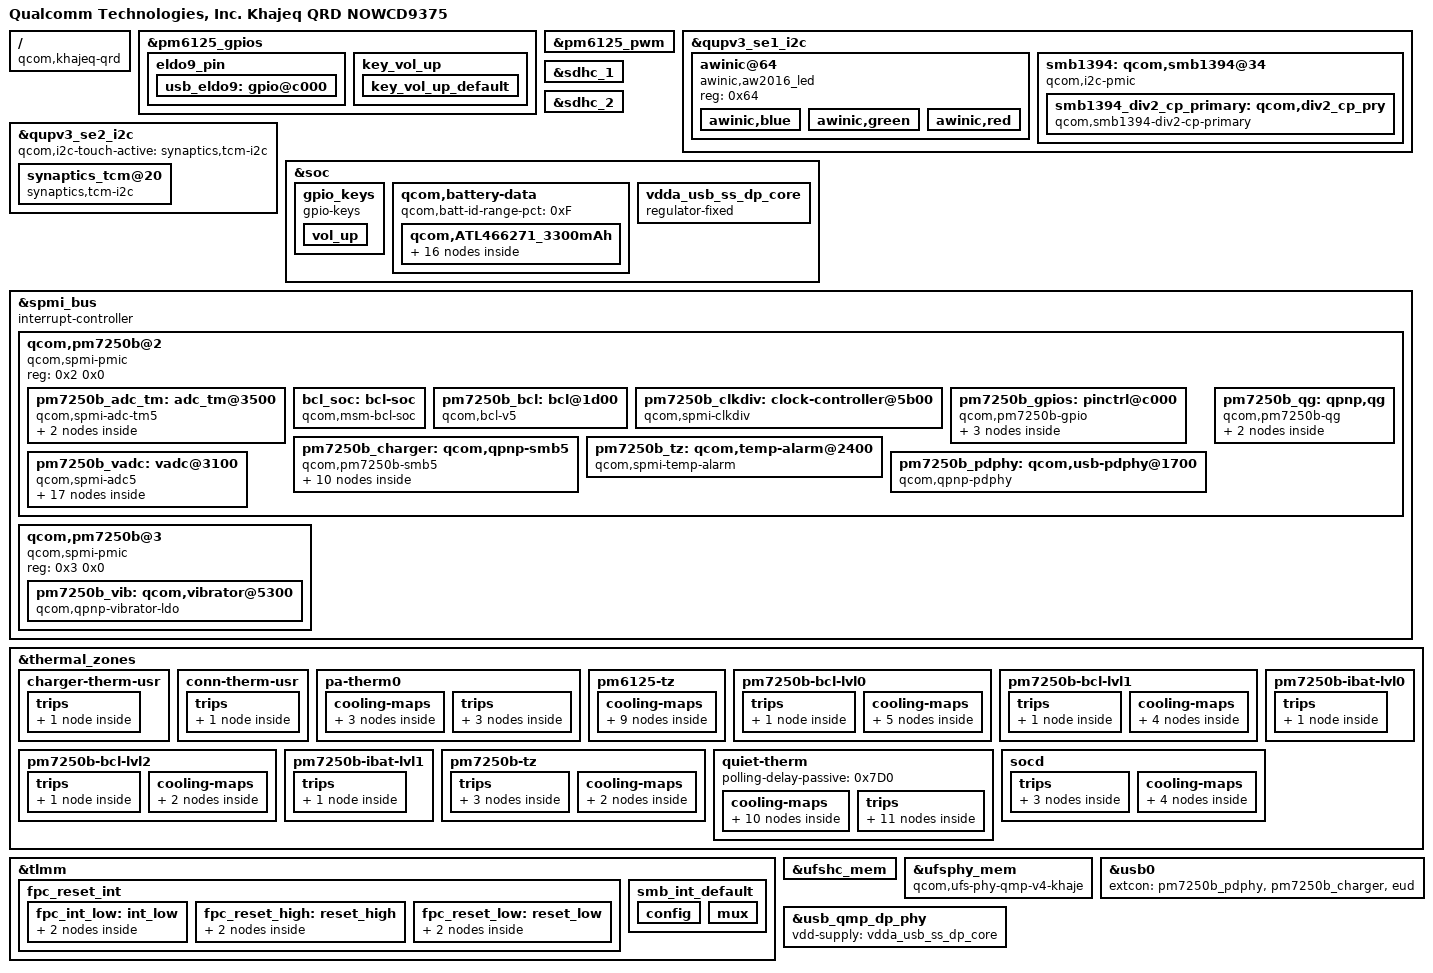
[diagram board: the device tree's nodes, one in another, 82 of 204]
/dts-v1/;

/ {
    compatible = "qcom,khajeq-qrd", "qcom,khajeq", "qcom,qrd";
    model = "Qualcomm Technologies, Inc. Khajeq QRD NOWCD9375";
    qcom,board-id = <0x2010B 0x0>;
    qcom,msm-id = <0x232 0x10000>;
    qcom,pmic-id = <0x2D 0x2E 0x0 0x0>;
};

&pm6125_gpios {
    eldo9_pin {
        usb_eldo9: gpio@c000 {
            bias-disable;
            function = "normal";
            output-high;
            pins = "gpio1";
            power-source = <0x0>;
            qcom,drive-strength = <0x2>;
        };
    };
    key_vol_up {
        key_vol_up_default: key_vol_up_default {
            bias-pull-up;
            function = "normal";
            input-enable;
            pins = "gpio5";
            power-source = <0x0>;
        };
    };
};

&pm6125_pwm {
    status = "ok";
};

&qupv3_se1_i2c {
    status = "ok";
    awinic@64 {
        compatible = "awinic,aw2016_led";
        reg = <0x64>;
        awinic,blue {
            awinic,fall-time-ms = <0x6>;
            awinic,hold-time-ms = <0x0>;
            awinic,id = <0x2>;
            awinic,imax = <0x2>;
            awinic,led-current = <0x3>;
            awinic,max-brightness = <0xFF>;
            awinic,name = "blue";
            awinic,off-time-ms = <0x4>;
            awinic,rise-time-ms = <0x6>;
        };
        awinic,green {
            awinic,fall-time-ms = <0x6>;
            awinic,hold-time-ms = <0x0>;
            awinic,id = <0x1>;
            awinic,imax = <0x2>;
            awinic,led-current = <0x3>;
            awinic,max-brightness = <0xFF>;
            awinic,name = "green";
            awinic,off-time-ms = <0x4>;
            awinic,rise-time-ms = <0x6>;
        };
        awinic,red {
            awinic,fall-time-ms = <0x6>;
            awinic,hold-time-ms = <0x0>;
            awinic,id = <0x0>;
            awinic,imax = <0x2>;
            awinic,led-current = <0x3>;
            awinic,max-brightness = <0xFF>;
            awinic,name = "red";
            awinic,off-time-ms = <0x4>;
            awinic,rise-time-ms = <0x6>;
        };
    };
    smb1394: qcom,smb1394@34 {
        #address-cells = <0x1>;
        #interrupt-cells = <0x3>;
        #size-cells = <0x0>;
        compatible = "qcom,i2c-pmic";
        interrupt-controller;
        interrupt-names = "smb1394";
        interrupt-parent = <&spmi_bus>;
        interrupts = <0x2 0xC5 0x0 0x8>;
        pinctrl-0 = <&pm7250b_smb_int_default>;
        pinctrl-names = "default";
        qcom,enable-toggle-stat;
        qcom,periph-map = <0x6 0x26 0x27>;
        reg = <0x34>;
        status = "ok";
        smb1394_div2_cp_primary: qcom,div2_cp_pry {
            #io-channel-cells = <0x1>;
            compatible = "qcom,smb1394-div2-cp-primary";
            interrupt-names = "temp-shdwn", "div2-irev", "usbin-uv", "usbin-ov", "div2-ilim", "div2-win-uv", "div2-win-ov";
            interrupts = <0x26 0x1 0x1 0x26 0x3 0x1 0x26 0x5 0x1 0x26 0x7 0x1 0x27 0x5 0x1 0x27 0x6 0x1 0x27 0x7 0x1>;
            io-channel-names = "die_temp";
            io-channels = <&pm7250b_vadc 0xE>;
            qcom,div2-cp-min-ilim-ua = <0xF4240>;
            qcom,parallel-input-mode = <0x1>;
            qcom,parallel-output-mode = <0x2>;
            status = "ok";
        };
    };
};

&qupv3_se2_i2c {
    qcom,i2c-touch-active = "synaptics,tcm-i2c";
    status = "okay";
    synaptics_tcm@20 {
        compatible = "synaptics,tcm-i2c";
        interrupt-parent = <&tlmm>;
        interrupts = <0x50 0x2008>;
        pinctrl-0 = <&ts_int_active &ts_reset_active>;
        pinctrl-1 = <&ts_int_suspend &ts_reset_suspend>;
        pinctrl-2 = <&ts_release>;
        pinctrl-names = "pmx_ts_active", "pmx_ts_suspend", "pmx_ts_release";
        reg = <0x20>;
        synaptics,extend_report;
        synaptics,firmware-name = "synaptics_firmware_k.img";
        synaptics,irq-gpio = <&tlmm 0x50 0x2008>;
        synaptics,irq-on-state = <0x0>;
        synaptics,power-delay-ms = <0xC8>;
        synaptics,reset-active-ms = <0x14>;
        synaptics,reset-delay-ms = <0xC8>;
        synaptics,reset-gpio = <&tlmm 0x56 0x0>;
        synaptics,reset-on-state = <0x0>;
        synaptics,ubl-i2c-addr = <0x20>;
    };
};

&sdhc_1 {
    pinctrl-0 = <&sdc1_on>;
    pinctrl-1 = <&sdc1_off>;
    pinctrl-names = "default", "sleep";
    qcom,vdd-current-level = <0x0 0x8B290>;
    qcom,vdd-io-always-on;
    qcom,vdd-io-current-level = <0x0 0x4F588>;
    qcom,vdd-io-lpm-sup;
    qcom,vdd-io-voltage-level = <0x1B7740 0x1B7740>;
    qcom,vdd-voltage-level = <0x2D2A80 0x2D2A80>;
    status = "ok";
    vdd-io-supply = <&L11A>;
    vdd-supply = <&L24A>;
};

&sdhc_2 {
    cd-gpios = <&tlmm 0x58 0x1>;
    pinctrl-0 = <&sdc2_on>;
    pinctrl-1 = <&sdc2_off>;
    pinctrl-names = "default", "sleep";
    qcom,vdd-current-level = <0x0 0xC3500>;
    qcom,vdd-io-bias-current-level = <0x0 0x1770>;
    qcom,vdd-io-bias-voltage-level = <0x132A40 0x132A40>;
    qcom,vdd-io-current-level = <0x0 0x55F0>;
    qcom,vdd-io-voltage-level = <0x1B7740 0x2D2A80>;
    qcom,vdd-voltage-level = <0x2D2A80 0x2D2A80>;
    status = "ok";
    vdd-io-bias-supply = <&L7A>;
    vdd-io-supply = <&L5A>;
    vdd-supply = <&L22A>;
};

&soc {
    gpio_keys {
        compatible = "gpio-keys";
        label = "gpio-keys";
        pinctrl-0 = <&key_vol_up_default>;
        pinctrl-names = "default";
        vol_up {
            debounce-interval = <0xF>;
            gpio-key,wakeup;
            gpios = <&pm6125_gpios 0x5 0x1>;
            label = "volume_up";
            linux,can-disable;
            linux,code = <0x73>;
            linux,input-type = <0x1>;
        };
    };
    qcom,battery-data {
        qcom,batt-id-range-pct = <0xF>;
        qcom,ATL466271_3300mAh {
            qcom,batt-id-kohm = <0x18>;
            qcom,battery-beta = <0x109A>;
            qcom,battery-therm-kohm = <0x64>;
            qcom,battery-type = "ATL466271_3300mAh_averaged_MasterSlave_Jun12th2019";
            qcom,fastchg-current-ma = <0x1F40>;
            qcom,fg-cc-cv-threshold-uv = <0x42FC70>;
            qcom,jeita-fcc-ranges = <0x0 0x64 0x186A00 0x65 0xC8 0x30D400 0xC9 0x1C2 0x7A1200 0x1C3 0x226 0x186A00>;
            qcom,jeita-fv-ranges = <0x0 0x64 0x432380 0x65 0xC8 0x432380 0xC9 0x1C2 0x432380 0x1C3 0x226 0x3DCC50>;
            qcom,jeita-hard-thresholds = <0x58CD 0x181D>;
            qcom,jeita-soft-fcc-ua = <0x186A00 0x186A00>;
            qcom,jeita-soft-fv-uv = <0x432380 0x3DCC50>;
            qcom,jeita-soft-hys-thresholds = <0x48D4 0x23C0>;
            qcom,jeita-soft-thresholds = <0x4CCC 0x20B8>;
            qcom,max-voltage-uv = <0x432380>;
            qcom,ocv-based-step-chg;
            qcom,qg-batt-profile-ver = <0x64>;
            qcom,step-chg-ranges = <0x3567E0 0x3D0900 0x7A1200 0x3D0901 0x401640 0x5B8D80 0x401641 0x432380 0x3D0900>;
            qcom,fcc1-temp-lut {
                qcom,lut-col-legend = <0x0 0xA 0x19 0x28 0x32>;
                qcom,lut-data = <0xC77 0xCBC 0xCF8 0xD1A 0xD26>;
            };
            qcom,fcc2-temp-lut {
                qcom,lut-col-legend = <0xFFFFFFF6 0x0 0xA 0x19 0x28 0x32>;
                qcom,lut-data = <0xCEB 0xCED 0xCFC 0xD04 0xD02 0xCFE>;
            };
            qcom,pc-temp-v1-lut {
                qcom,lut-col-legend = <0x0 0xA 0x19 0x28 0x32>;
                qcom,lut-data = <0xAABE 0xAB31 0xAB85 0xABA1 0xABA6 0xA9D1 0xAA55 0xAABA 0xAAC9 0xAACB 0xA8E5 0xA974 0xA9E1 0xA9F5 0xA9F6 0xA7FB 0xA88E 0xA903 0xA91E 0xA923 0xA717 0xA7A6 0xA81E 0xA83E 0xA847 0xA636 0xA6BF 0xA734 0xA755 0xA762 0xA558 0xA5D9 0xA64D 0xA66E 0xA67C 0xA47D 0xA4F6 0xA565 0xA587 0xA596 0xA3A6 0xA418 0xA481 0xA4A1 0xA4B1 0xA2D4 0xA33D 0xA39E 0xA3BD 0xA3CD 0xA204 0xA266 0xA2BF 0xA2DA 0xA2E9 0xA13E 0xA190 0xA1E6 0xA1FB 0xA209 0xA08F 0xA0C7 0xA110 0xA11F 0xA12D 0x9FEF 0xA01B 0xA043 0xA04B 0xA057 0x9F34 0x9F77 0x9F7F 0x9F81 0x9F88 0x9E33 0x9EB1 0x9EBE 0x9EBF 0x9EC2 0x9D2B 0x9DB3 0x9DF2 0x9DFA 0x9E00 0x9C6F 0x9CC8 0x9D20 0x9D31 0x9D43 0x9BE1 0x9C2A 0x9C67 0x9C75 0x9C8C 0x9B5A 0x9BA5 0x9BD5 0x9BD6 0x9BE5 0x9AD5 0x9AF4 0x9B3E 0x9B3E 0x9B44 0x9A4A 0x99EA 0x9A67 0x9A7A 0x9A82 0x9997 0x98F7 0x995C 0x9976 0x9983 0x9891 0x986A 0x9890 0x9896 0x989E 0x97B9 0x9802 0x9804 0x97FD 0x9801 0x975C 0x979E 0x978E 0x977F 0x9782 0x9720 0x973A 0x971E 0x970C 0x970B 0x96E4 0x96DD 0x96B8 0x96A6 0x969F 0x96A6 0x9688 0x965B 0x9647 0x963C 0x9668 0x963B 0x9606 0x95EC 0x95DF 0x962D 0x95F7 0x95BA 0x9599 0x958A 0x95F4 0x95BA 0x9575 0x954F 0x953D 0x95C1 0x9584 0x9537 0x950C 0x94F6 0x9594 0x9554 0x94FF 0x94CF 0x94B4 0x956B 0x952B 0x94CF 0x949B 0x9479 0x9546 0x9502 0x94A1 0x9468 0x943F 0x9526 0x94DF 0x9474 0x942D 0x93F9 0x94FF 0x94B7 0x9446 0x93ED 0x93A8 0x94BA 0x9476 0x9407 0x93A1 0x934F 0x9456 0x940F 0x93AA 0x9341 0x92EE 0x93E8 0x939C 0x933C 0x92D3 0x9282 0x9368 0x931F 0x92C3 0x9251 0x9200 0x92D8 0x9292 0x9239 0x91BE 0x916C 0x9233 0x91E7 0x9196 0x9120 0x90CF 0x91AD 0x9162 0x910F 0x90AD 0x9064 0x9162 0x911C 0x90C5 0x9070 0x9036 0x914D 0x9107 0x90B3 0x905E 0x9023 0x9138 0x90FA 0x90A3 0x9051 0x9014 0x9120 0x90DE 0x908D 0x9033 0x8FED 0x90BD 0x905A 0x900F 0x8F73 0x8F0F 0x8F42 0x8EE2 0x8EAE 0x8DFB 0x8D92 0x8D63 0x8CF6 0x8CC9 0x8C13 0x8BA7 0x8AF6 0x8A79 0x8A63 0x899D 0x892C 0x87A9 0x870E 0x870E 0x863A 0x85C2 0x8279 0x8194 0x81C9 0x80DD 0x8053 0x7530 0x7530 0x7530 0x7530 0x7530>;
                qcom,lut-row-legend = <0x2710 0x2648 0x2580 0x24B8 0x23F0 0x2328 0x2260 0x2198 0x20D0 0x2008 0x1F40 0x1E78 0x1DB0 0x1CE8 0x1C20 0x1B58 0x1A90 0x19C8 0x1900 0x1838 0x1770 0x16A8 0x15E0 0x1518 0x1450 0x1388 0x12C0 0x11F8 0x1130 0x1068 0xFA0 0xED8 0xE10 0xD48 0xC80 0xBB8 0xAF0 0xA28 0x960 0x898 0x7D0 0x708 0x640 0x578 0x4B0 0x3E8 0x384 0x320 0x2BC 0x258 0x1F4 0x190 0x12C 0xC8 0x64 0x0>;
            };
            qcom,pc-temp-v2-lut {
                qcom,lut-col-legend = <0xFFFFFFF6 0x0 0xA 0x19 0x28 0x32>;
                qcom,lut-data = <0xABC7 0xABAE 0xAB9A 0xAB81 0xAB4F 0xAB3B 0xAA5E 0xAA7F 0xAA93 0xAA8F 0xAA61 0xAA4C 0xA90F 0xA961 0xA992 0xA9A0 0xA977 0xA962 0xA7DC 0xA854 0xA89A 0xA8B4 0xA88E 0xA87A 0xA6C0 0xA759 0xA7A9 0xA7CC 0xA7A9 0xA797 0xA5C0 0xA664 0xA6BA 0xA6E4 0xA6C3 0xA6B3 0xA4EC 0xA56E 0xA5CE 0xA5FA 0xA5DA 0xA5CB 0xA424 0xA47E 0xA4E4 0xA511 0xA4F1 0xA4E2 0xA32C 0xA399 0xA3FE 0xA42B 0xA40B 0xA3FC 0xA1F2 0xA2BE 0xA31B 0xA347 0xA326 0xA317 0xA113 0xA1E8 0xA23B 0xA266 0xA245 0xA236 0xA0C1 0xA113 0xA15E 0xA188 0xA166 0xA159 0xA080 0xA042 0xA086 0xA0AE 0xA08C 0xA07F 0x9FC8 0x9F80 0x9FC3 0x9FE2 0x9FBD 0x9FAD 0x9DFF 0x9ECD 0x9F10 0x9F20 0x9EF6 0x9EE0 0x9C62 0x9E0A 0x9E4D 0x9E59 0x9E2F 0x9E18 0x9B6C 0x9D1D 0x9D64 0x9D7F 0x9D60 0x9D55 0x9AA1 0x9C1F 0x9C72 0x9CAA 0x9C97 0x9C98 0x99EE 0x9B36 0x9BA1 0x9BF6 0x9BE8 0x9BE9 0x9950 0x9A5B 0x9AE4 0x9B57 0x9B4A 0x9B46 0x98A2 0x9989 0x9A20 0x9A9F 0x9A94 0x9A8E 0x97B0 0x98BC 0x9940 0x99A8 0x99A0 0x999B 0x96B8 0x97FC 0x9869 0x98B1 0x98AA 0x98A8 0x961A 0x975B 0x97BD 0x97FA 0x97F7 0x97F5 0x95A6 0x96D1 0x972B 0x9760 0x9763 0x9762 0x9552 0x964D 0x96AA 0x96DD 0x96E3 0x96E1 0x9514 0x95BF 0x9635 0x966A 0x9671 0x966F 0x94E1 0x953C 0x95CC 0x9603 0x960A 0x9607 0x94AE 0x94E0 0x956D 0x95A4 0x95AA 0x95A7 0x947E 0x949B 0x9516 0x954D 0x9550 0x954C 0x9450 0x9464 0x94C2 0x94FC 0x94FE 0x94F9 0x9425 0x9436 0x946C 0x94B0 0x94B3 0x94AE 0x93FA 0x940D 0x9421 0x9469 0x946B 0x9465 0x93CC 0x93E5 0x93EE 0x9425 0x9426 0x941A 0x939D 0x93BF 0x93C7 0x93E3 0x93E2 0x93CD 0x936B 0x9395 0x939E 0x939D 0x938F 0x9371 0x9338 0x9367 0x9373 0x9353 0x9324 0x92F9 0x92FF 0x9332 0x9342 0x9305 0x92B7 0x9281 0x92BA 0x92F3 0x9300 0x92B7 0x925D 0x9222 0x9268 0x92A6 0x92AB 0x9265 0x920A 0x91CD 0x9209 0x9249 0x9247 0x9206 0x91AA 0x916C 0x9194 0x91C9 0x91CA 0x9195 0x913A 0x90F9 0x9118 0x9139 0x913D 0x910F 0x90B5 0x9073 0x90A3 0x90A2 0x90A1 0x907B 0x901F 0x8FDE 0x9044 0x9036 0x904B 0x902C 0x8FE9 0x8FB0 0x8FF7 0x8FF9 0x9023 0x9015 0x8FD2 0x8F9A 0x8FCC 0x8FDB 0x900B 0x9003 0x8FC1 0x8F8D 0x8F99 0x8FB2 0x8FEE 0x8FEB 0x8FAB 0x8F72 0x8F47 0x8F71 0x8FA7 0x8FAB 0x8F54 0x8EF5 0x8E7B 0x8EC7 0x8EC2 0x8EC8 0x8E26 0x8DA8 0x8CE2 0x8D4D 0x8D1F 0x8D25 0x8C61 0x8BD5 0x8AAB 0x8B3F 0x8AFB 0x8B0C 0x8A2A 0x898B 0x87CE 0x8898 0x882F 0x885D 0x8749 0x8695 0x83F8 0x84E8 0x848F 0x84CC 0x837A 0x8280 0x7E9C 0x7FC7 0x7F37 0x7F8A 0x7C60 0x7A4F 0x6E37 0x709F 0x6B82 0x6FA3 0x6CA6 0x6B7E>;
                qcom,lut-row-legend = <0x2710 0x2648 0x2580 0x24B8 0x23F0 0x2328 0x2260 0x2198 0x20D0 0x2008 0x1F40 0x1E78 0x1DB0 0x1CE8 0x1C20 0x1B58 0x1A90 0x19C8 0x1900 0x1838 0x1770 0x16A8 0x15E0 0x1518 0x1450 0x1388 0x12C0 0x11F8 0x1130 0x1068 0xFA0 0xED8 0xE10 0xD48 0xC80 0xBB8 0xAF0 0xA28 0x960 0x898 0x7D0 0x708 0x640 0x578 0x4B0 0x3E8 0x384 0x320 0x2BC 0x258 0x1F4 0x190 0x12C 0xC8 0x64 0x0>;
            };
            qcom,pc-temp-y1-lut {
                qcom,lut-col-legend = <0xFFFFFFF6 0x0 0xA 0x19 0x28 0x32>;
                qcom,lut-data = <0x16BD 0x14E3 0x13AD 0x1242 0x1181 0x114B 0x16D3 0x14E7 0x13AC 0x1240 0x1184 0x114D 0x16E9 0x14EB 0x13AB 0x123E 0x1185 0x114E 0x16FB 0x14F1 0x13A9 0x123B 0x1185 0x114E 0x1709 0x14F5 0x13A7 0x1238 0x1184 0x114F 0x170F 0x14F7 0x13A6 0x1234 0x1182 0x114F 0x170C 0x14F7 0x13A1 0x1230 0x117D 0x114E 0x1707 0x14F5 0x139B 0x122A 0x1179 0x114D 0x1708 0x14F4 0x1396 0x1226 0x1178 0x114B 0x170D 0x14EF 0x1392 0x1223 0x1178 0x1149 0x170F 0x14EC 0x1390 0x1220 0x1178 0x1147 0x1710 0x14EE 0x1393 0x121D 0x1176 0x1146 0x1714 0x14F1 0x1397 0x121A 0x1174 0x1146 0x1717 0x14F1 0x1395 0x1218 0x1173 0x1145 0x1720 0x14EF 0x138C 0x1216 0x1171 0x1143 0x1725 0x14EE 0x1388 0x1215 0x1170 0x1143 0x1722 0x14F5 0x138B 0x1215 0x1170 0x1143 0x171D 0x14FE 0x138F 0x1215 0x1170 0x1143 0x171D 0x1500 0x1390 0x1215 0x1170 0x1143 0x171C 0x14FD 0x138D 0x1216 0x1171 0x1143 0x171A 0x14FC 0x138B 0x1217 0x1171 0x1143 0x171A 0x1501 0x138C 0x1219 0x1173 0x1144 0x171C 0x1506 0x138D 0x121B 0x1175 0x1146 0x171D 0x1507 0x138D 0x121E 0x1175 0x1146 0x171D 0x1506 0x138E 0x1220 0x1175 0x1146 0x171D 0x1506 0x1390 0x1223 0x1176 0x1147 0x171B 0x150E 0x1395 0x1226 0x1178 0x1147 0x1717 0x1518 0x139B 0x122A 0x117A 0x1148 0x1713 0x1519 0x13A0 0x122E 0x117C 0x114A 0x170C 0x1516 0x13A5 0x1233 0x117F 0x114C 0x1708 0x1513 0x13A8 0x1238 0x1181 0x114E 0x1712 0x1513 0x13A8 0x123D 0x1184 0x114F 0x1722 0x1516 0x13A8 0x1243 0x1187 0x1150 0x172C 0x1519 0x13AB 0x1247 0x118A 0x1152 0x1737 0x151B 0x13B3 0x124A 0x118D 0x1155 0x173A 0x151D 0x13B7 0x124E 0x1190 0x1158 0x172D 0x1519 0x13B7 0x1253 0x1193 0x115A 0x1718 0x1513 0x13B8 0x1257 0x1195 0x115C 0x170D 0x1511 0x13BD 0x125D 0x1198 0x115D 0x1704 0x1511 0x13C5 0x1263 0x119A 0x115E 0x16FF 0x1511 0x13C9 0x1266 0x119D 0x1160 0x1708 0x1512 0x13C8 0x1269 0x119F 0x1163 0x170C 0x1516 0x13CA 0x126B 0x11A1 0x1163 0x16FB 0x152A 0x13D7 0x126D 0x11A3 0x1163 0x171B 0x1522 0x13D3 0x1275 0x11A6 0x1166 0x1712 0x1517 0x13E1 0x1276 0x11A9 0x1168 0x170B 0x151A 0x13E0 0x1277 0x11A7 0x1169 0x1705 0x1518 0x13D9 0x127E 0x11AA 0x1169 0x1706 0x1528 0x13DA 0x1281 0x11A9 0x1169 0x1705 0x152E 0x13E1 0x127F 0x11AB 0x116A 0x173F 0x151B 0x13EB 0x1282 0x11AD 0x116C 0x175A 0x1523 0x13EC 0x1290 0x11B1 0x116E 0x1737 0x151E 0x13F3 0x128C 0x11B6 0x1170 0x1743 0x152C 0x13F4 0x1295 0x11B8 0x1175 0x1743 0x152C 0x13F4 0x1295 0x11B8 0x1175 0x1743 0x152C 0x13F4 0x1295 0x11B8 0x1175>;
                qcom,lut-row-legend = <0x2710 0x2648 0x2580 0x24B8 0x23F0 0x2328 0x2260 0x2198 0x20D0 0x2008 0x1F40 0x1E78 0x1DB0 0x1CE8 0x1C20 0x1B58 0x1A90 0x19C8 0x1900 0x1838 0x1770 0x16A8 0x15E0 0x1518 0x1450 0x1388 0x12C0 0x11F8 0x1130 0x1068 0xFA0 0xED8 0xE10 0xD48 0xC80 0xBB8 0xAF0 0xA28 0x960 0x898 0x7D0 0x708 0x640 0x578 0x4B0 0x3E8 0x384 0x320 0x2BC 0x258 0x1F4 0x190 0x12C 0xC8 0x64 0x0>;
            };
            qcom,pc-temp-y2-lut {
                qcom,lut-col-legend = <0xFFFFFFF6 0x0 0xA 0x19 0x28 0x32>;
                qcom,lut-data = <0x276B 0x2807 0x290D 0x2A0F 0x2A21 0x2AAF 0x2765 0x2813 0x2904 0x29F4 0x2A37 0x2ACE 0x2762 0x2822 0x28F9 0x29D7 0x2A42 0x2ADE 0x2762 0x2830 0x28EF 0x29BC 0x2A45 0x2AE2 0x2764 0x283D 0x28E6 0x29A5 0x2A42 0x2ADE 0x2768 0x2845 0x28DF 0x2993 0x2A3D 0x2AD7 0x2791 0x284A 0x28DA 0x2986 0x2A23 0x2AC4 0x27D4 0x284E 0x28D6 0x297B 0x2A02 0x2AA8 0x2802 0x284D 0x28D4 0x296E 0x29FC 0x2A8B 0x2845 0x2846 0x28D0 0x295D 0x29FD 0x2A66 0x2867 0x2842 0x28CE 0x2952 0x29FE 0x2A51 0x286C 0x286D 0x28D3 0x2955 0x29F8 0x2A52 0x2879 0x28C1 0x28DE 0x295C 0x29EF 0x2A55 0x2872 0x2914 0x28F2 0x295C 0x29EE 0x2A51 0x281B 0x2979 0x291D 0x2959 0x29ED 0x2A46 0x27D4 0x29AF 0x2951 0x295F 0x29ED 0x2A40 0x2709 0x29B5 0x2996 0x297E 0x29ED 0x2A48 0x25FC 0x29B7 0x29D5 0x29AE 0x29EE 0x2A55 0x25CD 0x29BA 0x29EC 0x29F5 0x29EC 0x2A5F 0x25C7 0x29C1 0x29F9 0x2A59 0x29E9 0x2A69 0x25C4 0x29C4 0x29FE 0x2A7D 0x29F0 0x2A79 0x25C2 0x29C7 0x29FB 0x2A4C 0x2A51 0x2AA2 0x25C0 0x29CD 0x29F7 0x2A17 0x2ABC 0x2AD5 0x25BF 0x29CA 0x2A02 0x2A20 0x2ACC 0x2AF7 0x25BD 0x29B4 0x2A19 0x2A48 0x2AD0 0x2B16 0x25BC 0x2990 0x2A28 0x2A69 0x2AD5 0x2B2E 0x25BB 0x2937 0x2A2E 0x2A80 0x2ADC 0x2B46 0x25BA 0x28B0 0x2A35 0x2A94 0x2AE4 0x2B5E 0x25B9 0x282F 0x2A44 0x2AA4 0x2AF2 0x2B71 0x25B8 0x2796 0x2A5F 0x2AB2 0x2B0D 0x2B81 0x25B8 0x271A 0x2A6A 0x2AC4 0x2B28 0x2B94 0x25B7 0x26B9 0x2A5C 0x2AED 0x2B45 0x2BB1 0x25B7 0x2669 0x2A48 0x2B0E 0x2B61 0x2BCA 0x25B6 0x263F 0x2A37 0x2B0D 0x2B81 0x2BD4 0x25B6 0x2621 0x2A22 0x2B03 0x2BA2 0x2BDA 0x25B6 0x2609 0x2A10 0x2AFD 0x2BA9 0x2BDC 0x25B6 0x25F4 0x2A01 0x2B03 0x2B83 0x2BC0 0x25B6 0x25E3 0x29F1 0x2B09 0x2B5E 0x2BA2 0x25B5 0x25D9 0x29D8 0x2B04 0x2B58 0x2B99 0x25B5 0x25D1 0x29B3 0x2AF4 0x2B55 0x2B88 0x25B5 0x25CB 0x2978 0x2AE4 0x2B49 0x2B6E 0x25B5 0x25C7 0x28FB 0x2AD1 0x2B18 0x2B3A 0x25B5 0x25C3 0x2889 0x2AB8 0x2B01 0x2B30 0x25B5 0x25C0 0x282C 0x2A96 0x2AFA 0x2B58 0x25B5 0x25BD 0x27DD 0x2A73 0x2AF8 0x2AF5 0x25B4 0x25BB 0x27CD 0x2A44 0x2AB7 0x2ABD 0x25B4 0x25BB 0x27BA 0x2A5A 0x2A80 0x2A9B 0x25B4 0x25BA 0x281A 0x2A22 0x2A9B 0x2A92 0x25B4 0x25B9 0x2866 0x2A43 0x2AAE 0x2A9C 0x25B4 0x25B8 0x280A 0x2A47 0x2A7B 0x2A63 0x25B4 0x25B7 0x2735 0x29FE 0x2A4D 0x2A32 0x25B4 0x25B6 0x26F4 0x299B 0x29FE 0x2A0E 0x25B3 0x25B5 0x26A3 0x29EF 0x29C2 0x29B3 0x25B2 0x25B5 0x27BB 0x29B7 0x2949 0x2930 0x25B2 0x25B5 0x27BB 0x29B7 0x2949 0x2930 0x25B2 0x25B5 0x27BB 0x29B7 0x2949 0x2930>;
                qcom,lut-row-legend = <0x2710 0x2648 0x2580 0x24B8 0x23F0 0x2328 0x2260 0x2198 0x20D0 0x2008 0x1F40 0x1E78 0x1DB0 0x1CE8 0x1C20 0x1B58 0x1A90 0x19C8 0x1900 0x1838 0x1770 0x16A8 0x15E0 0x1518 0x1450 0x1388 0x12C0 0x11F8 0x1130 0x1068 0xFA0 0xED8 0xE10 0xD48 0xC80 0xBB8 0xAF0 0xA28 0x960 0x898 0x7D0 0x708 0x640 0x578 0x4B0 0x3E8 0x384 0x320 0x2BC 0x258 0x1F4 0x190 0x12C 0xC8 0x64 0x0>;
            };
            qcom,pc-temp-y3-lut {
                qcom,lut-col-legend = <0xFFFFFFF6 0x0 0xA 0x19 0x28 0x32>;
                qcom,lut-data = <0x36C4 0x34AD 0x3424 0x33EA 0x33DC 0x33D5 0x3658 0x34AC 0x3426 0x33EA 0x33DC 0x33D6 0x3617 0x34AA 0x3427 0x33EA 0x33DD 0x33D7 0x35F6 0x34A9 0x3428 0x33EA 0x33DD 0x33D8 0x35EA 0x34A7 0x3429 0x33EA 0x33DE 0x33DA 0x35E8 0x34A5 0x3429 0x33EA 0x33DE 0x33DA 0x3616 0x34A2 0x3429 0x33EA 0x33DE 0x33DB 0x365B 0x349F 0x3429 0x33E9 0x33DF 0x33DB 0x3639 0x34A0 0x3429 0x33EA 0x33DF 0x33DB 0x354E 0x34A5 0x3428 0x33EB 0x33DF 0x33DB 0x34BB 0x34A8 0x3427 0x33EC 0x33E0 0x33DB 0x34DF 0x349E 0x3427 0x33EE 0x33E0 0x33DC 0x3518 0x348E 0x3427 0x33F0 0x33E0 0x33DD 0x3525 0x3489 0x3428 0x33F1 0x33E1 0x33DD 0x3515 0x3482 0x342C 0x33F1 0x33E2 0x33DD 0x3506 0x347C 0x342E 0x33F2 0x33E2 0x33DD 0x34E8 0x347A 0x3428 0x33F2 0x33E2 0x33DD 0x34C3 0x3475 0x341F 0x33F4 0x33E3 0x33DD 0x34BF 0x346D 0x341D 0x33F5 0x33E4 0x33DE 0x34C6 0x345B 0x341C 0x33F6 0x33E5 0x33E0 0x34CD 0x3449 0x341A 0x33F7 0x33E6 0x33E1 0x34D1 0x343C 0x3413 0x33F2 0x33E2 0x33DE 0x34D3 0x3431 0x340B 0x33EB 0x33DE 0x33DB 0x34D3 0x3428 0x3407 0x33E8 0x33DD 0x33DA 0x34DD 0x3421 0x3404 0x33E6 0x33DD 0x33D9 0x34F1 0x341A 0x3402 0x33E5 0x33DC 0x33D8 0x3519 0x3408 0x33FF 0x33E5 0x33DD 0x33D9 0x354E 0x33F3 0x33FD 0x33E5 0x33DD 0x33D9 0x3580 0x33E8 0x33FC 0x33E5 0x33DC 0x33D9 0x35B6 0x33D7 0x33FB 0x33E6 0x33DC 0x33D9 0x35EE 0x33D2 0x33F9 0x33E6 0x33DB 0x33D9 0x362A 0x33D4 0x33F7 0x33E5 0x33DB 0x33D9 0x3669 0x33D7 0x33F5 0x33E5 0x33DB 0x33D8 0x36AA 0x33DA 0x33F5 0x33E5 0x33DB 0x33D8 0x36EC 0x33DE 0x33F7 0x33E4 0x33DC 0x33D8 0x3736 0x33E4 0x33F9 0x33E4 0x33DD 0x33D8 0x378C 0x33EF 0x33FB 0x33E3 0x33DC 0x33D9 0x37E8 0x33FF 0x33FD 0x33E2 0x33DB 0x33D9 0x3845 0x3414 0x33FF 0x33E2 0x33DB 0x33D9 0x38A5 0x3432 0x3400 0x33E2 0x33DC 0x33DA 0x3904 0x3451 0x3401 0x33E2 0x33DC 0x33DA 0x395F 0x3468 0x3401 0x33E2 0x33DD 0x33DA 0x39BD 0x3483 0x3402 0x33E3 0x33DD 0x33DA 0x3A24 0x34B0 0x3405 0x33E4 0x33DC 0x33D9 0x3A96 0x34FD 0x340A 0x33E5 0x33DC 0x33DA 0x3A8C 0x351C 0x340E 0x33E8 0x33DE 0x33DC 0x3AD3 0x3551 0x3412 0x33E9 0x33DF 0x33DD 0x3B30 0x3590 0x341B 0x33EE 0x33E3 0x33DF 0x3B8F 0x35D8 0x3427 0x33F0 0x33E2 0x33DD 0x3BEC 0x3617 0x3428 0x33EF 0x33E0 0x33DC 0x3C53 0x3662 0x342B 0x33EF 0x33E1 0x33DD 0x3D0B 0x36EC 0x3437 0x33F2 0x33E4 0x33DF 0x3DF9 0x37B2 0x3448 0x33F8 0x33E6 0x33E3 0x4115 0x38C2 0x3473 0x3400 0x33EB 0x33E7 0x4115 0x38C2 0x3473 0x3400 0x33EB 0x33E7 0x4115 0x38C2 0x3473 0x3400 0x33EB 0x33E7>;
                qcom,lut-row-legend = <0x2710 0x2648 0x2580 0x24B8 0x23F0 0x2328 0x2260 0x2198 0x20D0 0x2008 0x1F40 0x1E78 0x1DB0 0x1CE8 0x1C20 0x1B58 0x1A90 0x19C8 0x1900 0x1838 0x1770 0x16A8 0x15E0 0x1518 0x1450 0x1388 0x12C0 0x11F8 0x1130 0x1068 0xFA0 0xED8 0xE10 0xD48 0xC80 0xBB8 0xAF0 0xA28 0x960 0x898 0x7D0 0x708 0x640 0x578 0x4B0 0x3E8 0x384 0x320 0x2BC 0x258 0x1F4 0x190 0x12C 0xC8 0x64 0x0>;
            };
            qcom,pc-temp-y4-lut {
                qcom,lut-col-legend = <0xFFFFFFF6 0x0 0xA 0x19 0x28 0x32>;
                qcom,lut-data = <0x4658 0x4267 0x414E 0x4074 0x404C 0x4048 0x4698 0x42A9 0x414F 0x4071 0x404B 0x4046 0x46BF 0x42D5 0x414D 0x406D 0x4049 0x4044 0x46D3 0x42EF 0x414A 0x4069 0x4047 0x4043 0x46DA 0x42FC 0x4145 0x4066 0x4045 0x4041 0x46DB 0x4300 0x413F 0x4065 0x4045 0x4040 0x466D 0x42F1 0x4135 0x4066 0x4044 0x4040 0x45C7 0x42D8 0x412B 0x4066 0x4044 0x403F 0x45E8 0x42C9 0x4129 0x4068 0x4044 0x4040 0x473B 0x42BB 0x4128 0x406A 0x4046 0x4041 0x484C 0x42B5 0x4128 0x406C 0x4047 0x4042 0x48BB 0x42D7 0x412B 0x4070 0x4049 0x4043 0x490C 0x431C 0x4131 0x4075 0x404D 0x4044 0x48AF 0x436C 0x4148 0x407D 0x4052 0x4045 0x46BB 0x43E8 0x4192 0x408A 0x4059 0x4049 0x4566 0x4426 0x41CE 0x409A 0x4061 0x404E 0x4536 0x43E3 0x41F3 0x40AA 0x4067 0x4054 0x4517 0x436B 0x420C 0x40BE 0x4070 0x405B 0x44DD 0x4316 0x4209 0x40E5 0x4084 0x406A 0x447E 0x42D4 0x41F0 0x4123 0x40AA 0x4084 0x43FF 0x4292 0x41C9 0x4139 0x40B8 0x408E 0x4307 0x4243 0x416A 0x40F4 0x4097 0x4079 0x41FB 0x41F9 0x4104 0x409E 0x406C 0x405C 0x41A6 0x41CD 0x40DF 0x407B 0x4059 0x404F 0x4182 0x41B2 0x40CB 0x4064 0x404D 0x4046 0x4173 0x4192 0x40C4 0x405E 0x4049 0x4044 0x4171 0x4157 0x40C2 0x405F 0x4049 0x4044 0x4171 0x4121 0x40C2 0x4060 0x4049 0x4044 0x4174 0x411D 0x40C3 0x4063 0x404B 0x4045 0x417B 0x412D 0x40C5 0x406A 0x404E 0x4047 0x4183 0x4139 0x40C5 0x4071 0x4053 0x404A 0x418F 0x4141 0x40AE 0x407A 0x4059 0x4050 0x419D 0x414D 0x4097 0x4080 0x4061 0x4056 0x41AD 0x415C 0x409A 0x4083 0x4068 0x405B 0x41BF 0x4171 0x40A8 0x4085 0x406F 0x405F 0x41CE 0x4181 0x40B8 0x4083 0x406F 0x405F 0x41DA 0x418D 0x40CB 0x406D 0x405A 0x4051 0x41E5 0x4197 0x40D9 0x4059 0x4046 0x4043 0x41ED 0x419A 0x40D8 0x4056 0x4042 0x4043 0x41F3 0x4198 0x40D7 0x4054 0x4041 0x4044 0x41F5 0x4194 0x40D7 0x4055 0x4040 0x4044 0x41EC 0x4182 0x40E0 0x405A 0x4041 0x4043 0x41E1 0x4175 0x40EA 0x405F 0x4040 0x4040 0x41DC 0x4175 0x40F4 0x4061 0x403A 0x4033 0x41EF 0x4179 0x4105 0x4064 0x403C 0x4033 0x41FB 0x4195 0x410C 0x4072 0x4047 0x4045 0x422F 0x41BB 0x412A 0x407F 0x405B 0x4071 0x4276 0x41F1 0x415D 0x4099 0x4098 0x40B2 0x42B9 0x4250 0x41A2 0x40CE 0x40AD 0x4092 0x42C1 0x427C 0x41A0 0x40B3 0x405E 0x4053 0x4297 0x425F 0x41A1 0x40AA 0x405D 0x4055 0x4292 0x426E 0x41C2 0x40C8 0x4074 0x4068 0x42D1 0x42BA 0x4207 0x4109 0x40A9 0x40A0 0x4493 0x4351 0x42CC 0x41BC 0x417F 0x414E 0x4493 0x4351 0x42CC 0x41BC 0x417F 0x414E 0x4493 0x4351 0x42CC 0x41BC 0x417F 0x414E>;
                qcom,lut-row-legend = <0x2710 0x2648 0x2580 0x24B8 0x23F0 0x2328 0x2260 0x2198 0x20D0 0x2008 0x1F40 0x1E78 0x1DB0 0x1CE8 0x1C20 0x1B58 0x1A90 0x19C8 0x1900 0x1838 0x1770 0x16A8 0x15E0 0x1518 0x1450 0x1388 0x12C0 0x11F8 0x1130 0x1068 0xFA0 0xED8 0xE10 0xD48 0xC80 0xBB8 0xAF0 0xA28 0x960 0x898 0x7D0 0x708 0x640 0x578 0x4B0 0x3E8 0x384 0x320 0x2BC 0x258 0x1F4 0x190 0x12C 0xC8 0x64 0x0>;
            };
            qcom,pc-temp-y5-lut {
                qcom,lut-col-legend = <0xFFFFFFF6 0x0 0xA 0x19 0x28 0x32>;
                qcom,lut-data = <0x2DCF 0x2EA6 0x34C2 0x3F88 0x444D 0x35AF 0x2BB3 0x2F95 0x360A 0x3FB0 0x4531 0x3C53 0x2AC4 0x3098 0x374A 0x3F1A 0x4617 0x4249 0x2AC2 0x3191 0x3867 0x3E11 0x46DE 0x473E 0x2B6F 0x3261 0x3945 0x3CDC 0x4765 0x4ADC 0x2C8B 0x32EB 0x39C8 0x3BC4 0x478B 0x4CCD 0x30B1 0x332C 0x3A07 0x3A3F 0x4749 0x4D1B 0x35FE 0x335E 0x3A10 0x38B6 0x46C1 0x4C61 0x3566 0x33F5 0x399A 0x383B 0x45CB 0x4AA2 0x2DAF 0x3592 0x3854 0x3805 0x43D1 0x4729 0x28DE 0x3686 0x3710 0x37F6 0x41D5 0x44E7 0x2CED 0x333A 0x3627 0x38AA 0x4016 0x44BC 0x33A3 0x2E59 0x3538 0x3982 0x3E49 0x44CB 0x363C 0x2E2F 0x33DE 0x38A2 0x3C4B 0x438F 0x3618 0x31E6 0x31FD 0x357D 0x39F2 0x4097 0x357B 0x35B4 0x312D 0x33FD 0x3886 0x3DE5 0x336F 0x38DA 0x31CF 0x3416 0x37BF 0x3B27 0x312A 0x3B5B 0x3333 0x344E 0x373E 0x38EE 0x32DC 0x3B9A 0x364C 0x34FC 0x3748 0x38A8 0x384D 0x3AB3 0x3CA3 0x36F4 0x37AE 0x3927 0x3CAF 0x3A21 0x3FD6 0x3983 0x386E 0x3A1C 0x3CD7 0x3A4B 0x403C 0x3E29 0x3B30 0x3DAB 0x3AD5 0x3AA6 0x405E 0x420F 0x3F25 0x4203 0x3803 0x3B5D 0x4032 0x4223 0x4331 0x4443 0x302E 0x3D0B 0x3FD7 0x416A 0x479B 0x45EE 0x2C32 0x3E6A 0x3F8C 0x411B 0x4967 0x46BD 0x2C87 0x3C91 0x3EE4 0x40C5 0x4958 0x4704 0x2CF8 0x38B8 0x3E3E 0x4095 0x48B7 0x46F9 0x2D05 0x35A9 0x3E9C 0x415A 0x46FF 0x4685 0x2D1E 0x2F0D 0x3FFC 0x42BA 0x43BC 0x45C2 0x2D44 0x2C58 0x40B5 0x4323 0x4149 0x449D 0x2DC6 0x2CB5 0x3FFE 0x42A4 0x3F46 0x41AE 0x2E59 0x2D1E 0x3F20 0x4230 0x3E0B 0x3F37 0x2E84 0x2D75 0x3F46 0x4366 0x3FF7 0x3FC3 0x2ECC 0x2DD9 0x3FC7 0x4622 0x4519 0x4235 0x2F2B 0x2E2A 0x4027 0x46E8 0x4849 0x4567 0x3086 0x2E8B 0x406F 0x463E 0x4A2B 0x4B28 0x31FA 0x2F27 0x409C 0x4546 0x4B67 0x5113 0x322B 0x302E 0x403C 0x4411 0x4CD5 0x5545 0x320C 0x3218 0x3EF4 0x427C 0x4F28 0x58C3 0x31C4 0x331E 0x3D2F 0x410E 0x4FEF 0x595F 0x3044 0x31C5 0x3A0E 0x3F2B 0x503D 0x57B1 0x2E6A 0x2FE8 0x3821 0x3EA2 0x5092 0x58B7 0x2D32 0x2EAD 0x3748 0x3F17 0x521C 0x6103 0x2CDF 0x2EAF 0x36B6 0x3DC8 0x492E 0x50C2 0x2D8E 0x2E7F 0x3677 0x3E83 0x458D 0x4ED5 0x2D87 0x2F45 0x3572 0x3C42 0x42C6 0x44AF 0x2E40 0x3090 0x35E9 0x3E8F 0x3FC4 0x3A9E 0x30BC 0x3294 0x374B 0x3C46 0x3A32 0x3902 0x31D0 0x335F 0x37F3 0x3F80 0x457F 0x4378 0x2F31 0x3311 0x37CD 0x41E5 0x44DD 0x44D9 0x2DD6 0x323A 0x3777 0x4143 0x4ADE 0x45E1 0x2DFA 0x3117 0x3679 0x42F9 0x478D 0x47FD 0x2EC8 0x2FD4 0x3B77 0x423F 0x4578 0x43D7 0x2EC8 0x2FD4 0x3B77 0x423F 0x4578 0x43D7 0x2EC8 0x2FD4 0x3B77 0x423F 0x4578 0x43D7>;
                qcom,lut-row-legend = <0x2710 0x2648 0x2580 0x24B8 0x23F0 0x2328 0x2260 0x2198 0x20D0 0x2008 0x1F40 0x1E78 0x1DB0 0x1CE8 0x1C20 0x1B58 0x1A90 0x19C8 0x1900 0x1838 0x1770 0x16A8 0x15E0 0x1518 0x1450 0x1388 0x12C0 0x11F8 0x1130 0x1068 0xFA0 0xED8 0xE10 0xD48 0xC80 0xBB8 0xAF0 0xA28 0x960 0x898 0x7D0 0x708 0x640 0x578 0x4B0 0x3E8 0x384 0x320 0x2BC 0x258 0x1F4 0x190 0x12C 0xC8 0x64 0x0>;
            };
            qcom,pc-temp-y6-lut {
                qcom,lut-col-legend = <0xFFFFFFF6 0x0 0xA 0x19 0x28 0x32>;
                qcom,lut-data = <0x1997 0x15E0 0x1464 0x137E 0x134F 0x1342 0x1986 0x15E5 0x1460 0x137C 0x134E 0x1343 0x196F 0x15E5 0x145B 0x137A 0x134E 0x1343 0x1958 0x15E1 0x1455 0x1378 0x134E 0x1343 0x1946 0x15DA 0x144F 0x1377 0x134E 0x1344 0x193D 0x15D0 0x1449 0x1376 0x134E 0x1344 0x193C 0x15C2 0x1442 0x1375 0x134E 0x1344 0x193D 0x15B2 0x143B 0x1374 0x134E 0x1344 0x1932 0x15A9 0x1436 0x1375 0x134E 0x1344 0x1903 0x15A2 0x1431 0x1375 0x134E 0x1345 0x18E7 0x159F 0x142E 0x1376 0x134F 0x1345 0x1921 0x15A0 0x142D 0x1378 0x134F 0x1345 0x1975 0x15A3 0x142C 0x137B 0x1351 0x1346 0x1968 0x15AC 0x1431 0x137D 0x1352 0x1347 0x18DA 0x15C9 0x1447 0x1381 0x1355 0x1348 0x1872 0x15D9 0x1456 0x1386 0x1357 0x134A 0x1857 0x15C8 0x145A 0x138B 0x135A 0x134B 0x1844 0x15A7 0x145C 0x1391 0x135C 0x134E 0x1841 0x158A 0x145B 0x139D 0x1362 0x1352 0x183D 0x156E 0x1453 0x13B0 0x136E 0x135B 0x1837 0x1553 0x1446 0x13B6 0x1372 0x135E 0x180C 0x1537 0x1427 0x139F 0x1366 0x1356 0x17D5 0x151F 0x1405 0x1382 0x1357 0x134B 0x17D0 0x1515 0x13F9 0x1376 0x1351 0x1346 0x17E7 0x1511 0x13F3 0x136E 0x134D 0x1343 0x1802 0x150B 0x13F1 0x136C 0x134C 0x1342 0x182A 0x14FD 0x13F1 0x136D 0x134C 0x1342 0x185D 0x14EF 0x13F2 0x136E 0x134C 0x1343 0x188D 0x14EF 0x13F4 0x136F 0x134C 0x1343 0x18BF 0x14FE 0x13F8 0x1372 0x134D 0x1344 0x18F2 0x1512 0x13F9 0x1375 0x134E 0x1345 0x1926 0x152A 0x13F5 0x1378 0x1350 0x1346 0x195B 0x1548 0x13F2 0x137A 0x1352 0x1348 0x1992 0x1566 0x13F5 0x137C 0x1355 0x134A 0x19CB 0x1588 0x1400 0x137D 0x1358 0x134B 0x1A09 0x15AB 0x140D 0x137D 0x1358 0x134B 0x1A4C 0x15CF 0x1419 0x1377 0x1352 0x1348 0x1A93 0x15F5 0x1426 0x1372 0x134C 0x1344 0x1ADC 0x161E 0x142F 0x1372 0x134C 0x1344 0x1B26 0x164C 0x1438 0x1372 0x134C 0x1345 0x1B6E 0x167A 0x1442 0x1373 0x134C 0x1345 0x1BB1 0x16A7 0x1451 0x1376 0x134E 0x1346 0x1BF5 0x16DA 0x1463 0x1379 0x134E 0x1345 0x1C43 0x171B 0x1478 0x137B 0x134B 0x1341 0x1CA2 0x1773 0x1498 0x137F 0x134D 0x1342 0x1C9E 0x179D 0x149F 0x1386 0x1352 0x1349 0x1CE3 0x17D8 0x14B8 0x138B 0x1358 0x1356 0x1D3B 0x181D 0x14DD 0x1396 0x136D 0x136A 0x1D99 0x1875 0x1509 0x13A8 0x1372 0x1360 0x1DE8 0x18BB 0x1515 0x13A0 0x135A 0x134D 0x1E2F 0x18F8 0x1529 0x139F 0x135B 0x134F 0x1EC1 0x1975 0x155C 0x13AB 0x1365 0x1356 0x1F8E 0x1A2E 0x15A3 0x13C4 0x1376 0x136A 0x2295 0x1B2A 0x1631 0x1400 0x13B7 0x139F 0x2295 0x1B2A 0x1631 0x1400 0x13B7 0x139F 0x2295 0x1B2A 0x1631 0x1400 0x13B7 0x139F>;
                qcom,lut-row-legend = <0x2710 0x2648 0x2580 0x24B8 0x23F0 0x2328 0x2260 0x2198 0x20D0 0x2008 0x1F40 0x1E78 0x1DB0 0x1CE8 0x1C20 0x1B58 0x1A90 0x19C8 0x1900 0x1838 0x1770 0x16A8 0x15E0 0x1518 0x1450 0x1388 0x12C0 0x11F8 0x1130 0x1068 0xFA0 0xED8 0xE10 0xD48 0xC80 0xBB8 0xAF0 0xA28 0x960 0x898 0x7D0 0x708 0x640 0x578 0x4B0 0x3E8 0x384 0x320 0x2BC 0x258 0x1F4 0x190 0x12C 0xC8 0x64 0x0>;
            };
            qcom,pc-temp-z1-lut {
                qcom,lut-col-legend = <0x0 0xA 0x19 0x28 0x32>;
                qcom,lut-data = <0x2DFA 0x2B9F 0x290C 0x27D8 0x278B 0x2E1A 0x2BB9 0x2953 0x2821 0x27CE 0x2E1E 0x2BC0 0x2955 0x2823 0x27CF 0x2E1D 0x2BAF 0x294A 0x2823 0x27CF 0x2E10 0x2BA2 0x293D 0x281E 0x27CD 0x2E01 0x2B92 0x2931 0x2818 0x27C9 0x2DF5 0x2B7B 0x2929 0x2813 0x27C6 0x2DEB 0x2B6C 0x2922 0x280F 0x27C4 0x2DDF 0x2B67 0x291C 0x280B 0x27C2 0x2DD7 0x2B64 0x2918 0x280A 0x27C1 0x2DD2 0x2B64 0x2915 0x2809 0x27BF 0x2DCE 0x2B64 0x2912 0x2808 0x27BE 0x2DC9 0x2B64 0x2910 0x2808 0x27BD 0x2DC5 0x2B61 0x290F 0x2807 0x27BD 0x2DC2 0x2B5B 0x290E 0x2807 0x27BC 0x2DB8 0x2B59 0x290C 0x2805 0x27BC 0x2DAD 0x2B57 0x290B 0x2805 0x27BC 0x2DAD 0x2B57 0x290A 0x2805 0x27BC 0x2DB8 0x2B59 0x290A 0x2806 0x27BE 0x2DC2 0x2B5D 0x290D 0x2808 0x27BF 0x2DCE 0x2B62 0x2911 0x280C 0x27C1 0x2DDD 0x2B6A 0x2915 0x280E 0x27C3 0x2DE0 0x2B72 0x291A 0x2810 0x27C5 0x2DD9 0x2B78 0x291F 0x2812 0x27C7 0x2DD4 0x2B7D 0x2924 0x2814 0x27C9 0x2DD5 0x2B7E 0x2929 0x2818 0x27CB 0x2DD9 0x2B7C 0x292E 0x281B 0x27CE 0x2DDC 0x2B7B 0x2934 0x2820 0x27D2 0x2DDF 0x2B7D 0x2939 0x2824 0x27D5 0x2DE3 0x2B81 0x293E 0x2828 0x27D8 0x2DE6 0x2B86 0x2944 0x282D 0x27DB 0x2DEA 0x2B92 0x294B 0x2830 0x27DE 0x2DEE 0x2B9D 0x2953 0x2834 0x27E1 0x2DF9 0x2B9D 0x2958 0x2838 0x27E5 0x2E05 0x2B99 0x295D 0x283D 0x27E9 0x2E0D 0x2B97 0x2962 0x2842 0x27ED 0x2E14 0x2BA1 0x2968 0x2848 0x27F1 0x2E1B 0x2BAE 0x296E 0x284D 0x27F5 0x2E21 0x2BB1 0x2974 0x2852 0x27F9 0x2E28 0x2BB2 0x297B 0x2856 0x27FC 0x2E2B 0x2BB4 0x2981 0x285A 0x27FF 0x2E2D 0x2BBF 0x2986 0x285F 0x2803 0x2E2F 0x2BC8 0x298C 0x2864 0x2806 0x2E32 0x2BC6 0x2992 0x2866 0x2808 0x2E2C 0x2BCF 0x2998 0x2868 0x2809 0x2E2C 0x2BD4 0x299F 0x286B 0x280A 0x2E36 0x2BD9 0x29A4 0x286C 0x280C 0x2E28 0x2BE0 0x29A2 0x286E 0x280D 0x2E37 0x2BD8 0x29A6 0x2872 0x2811 0x2E50 0x2BD5 0x29AF 0x2876 0x2815 0x2E39 0x2BE1 0x29B1 0x287A 0x2819 0x2E48 0x2BF3 0x29B6 0x2880 0x281E 0x2E6D 0x2BF9 0x29C0 0x2886 0x2823 0x2E7A 0x2C18 0x29CE 0x288E 0x282A 0x2E7A 0x2C18 0x29CE 0x288E 0x282A 0x2E7A 0x2C18 0x29CE 0x288E 0x282A>;
                qcom,lut-row-legend = <0x2710 0x2648 0x2580 0x24B8 0x23F0 0x2328 0x2260 0x2198 0x20D0 0x2008 0x1F40 0x1E78 0x1DB0 0x1CE8 0x1C20 0x1B58 0x1A90 0x19C8 0x1900 0x1838 0x1770 0x16A8 0x15E0 0x1518 0x1450 0x1388 0x12C0 0x11F8 0x1130 0x1068 0xFA0 0xED8 0xE10 0xD48 0xC80 0xBB8 0xAF0 0xA28 0x960 0x898 0x7D0 0x708 0x640 0x578 0x4B0 0x3E8 0x384 0x320 0x2BC 0x258 0x1F4 0x190 0x12C 0xC8 0x64 0x0>;
            };
            qcom,pc-temp-z2-lut {
                qcom,lut-col-legend = <0x0 0xA 0x19 0x28 0x32>;
                qcom,lut-data = <0x26A6 0x261D 0x2732 0x277A 0x2869 0x26B9 0x26CC 0x271E 0x27B4 0x27F2 0x26D3 0x2713 0x2744 0x278C 0x27E6 0x26E9 0x2709 0x2755 0x275F 0x27DD 0x26E4 0x26F7 0x274F 0x2761 0x27DD 0x26CC 0x26F0 0x2742 0x2774 0x27E0 0x26B5 0x26EC 0x272C 0x2784 0x27E6 0x26A6 0x26EA 0x2704 0x278F 0x27F0 0x269A 0x26ED 0x26F3 0x2799 0x27FF 0x2697 0x26F3 0x26FB 0x27A2 0x2810 0x269F 0x26F7 0x2706 0x27AB 0x2826 0x26AB 0x26FA 0x270C 0x27B0 0x2835 0x26B4 0x26FF 0x2713 0x27B0 0x283E 0x26BB 0x277F 0x271A 0x27AF 0x2843 0x26C3 0x2841 0x2721 0x27B4 0x283F 0x26D1 0x284F 0x2725 0x27BB 0x2838 0x26DD 0x27A8 0x2724 0x27BA 0x2836 0x26DE 0x272C 0x271F 0x27B3 0x2836 0x26D8 0x2723 0x271D 0x27AE 0x2837 0x26D4 0x271D 0x2726 0x27C2 0x2843 0x26D4 0x271F 0x2737 0x27E4 0x285B 0x26D7 0x2741 0x2761 0x27E9 0x285E 0x26DC 0x275F 0x27AB 0x27DD 0x2839 0x26EA 0x275A 0x27C4 0x27C9 0x2806 0x26F5 0x274B 0x279D 0x278B 0x27C4 0x26F6 0x2744 0x276E 0x2742 0x2781 0x26F4 0x2744 0x2756 0x2739 0x2776 0x26F4 0x2745 0x2745 0x273E 0x2781 0x26F5 0x273E 0x2741 0x2746 0x278F 0x26F7 0x2731 0x274C 0x2750 0x279D 0x26F8 0x272D 0x275B 0x275D 0x27AE 0x26FA 0x2736 0x276B 0x2772 0x27C4 0x26FC 0x2744 0x277C 0x2791 0x27E0 0x26FF 0x2750 0x278F 0x27B3 0x2803 0x2704 0x275D 0x27A4 0x27DE 0x2835 0x2708 0x2767 0x27B8 0x2804 0x2869 0x270D 0x276F 0x27C7 0x2817 0x288C 0x2713 0x2776 0x27D3 0x2824 0x28A9 0x271C 0x2782 0x27E0 0x282F 0x28B1 0x2727 0x2792 0x27F2 0x283A 0x28A3 0x2728 0x2799 0x27FD 0x2842 0x2896 0x271E 0x2788 0x27EC 0x2844 0x2895 0x2718 0x277A 0x27D0 0x2843 0x2890 0x2716 0x277A 0x27CA 0x283A 0x2879 0x274A 0x278C 0x27D7 0x283B 0x2859 0x274D 0x278C 0x27DC 0x2845 0x2878 0x2746 0x2781 0x27E6 0x283D 0x2877 0x2744 0x276D 0x27DF 0x2870 0x2898 0x2737 0x2778 0x27F3 0x289D 0x28D4 0x26F4 0x27AB 0x27F4 0x281C 0x280E 0x2761 0x2791 0x27BB 0x27D1 0x27EA 0x2732 0x276F 0x2790 0x27B1 0x27BF 0x2709 0x273B 0x2777 0x2790 0x27A2 0x266C 0x2709 0x2749 0x2763 0x274F 0x266C 0x2709 0x2749 0x2763 0x274F 0x266C 0x2709 0x2749 0x2763 0x274F>;
                qcom,lut-row-legend = <0x2710 0x2648 0x2580 0x24B8 0x23F0 0x2328 0x2260 0x2198 0x20D0 0x2008 0x1F40 0x1E78 0x1DB0 0x1CE8 0x1C20 0x1B58 0x1A90 0x19C8 0x1900 0x1838 0x1770 0x16A8 0x15E0 0x1518 0x1450 0x1388 0x12C0 0x11F8 0x1130 0x1068 0xFA0 0xED8 0xE10 0xD48 0xC80 0xBB8 0xAF0 0xA28 0x960 0x898 0x7D0 0x708 0x640 0x578 0x4B0 0x3E8 0x384 0x320 0x2BC 0x258 0x1F4 0x190 0x12C 0xC8 0x64 0x0>;
            };
            qcom,pc-temp-z3-lut {
                qcom,lut-col-legend = <0x0 0xA 0x19 0x28 0x32>;
                qcom,lut-data = <0x4C2C 0x4BF4 0x4BAA 0x4B97 0x4B71 0x4CAA 0x4C40 0x4BCA 0x4B99 0x4B8C 0x4CDD 0x4C68 0x4BE2 0x4BA2 0x4B94 0x4CFA 0x4C72 0x4BEB 0x4BA9 0x4B99 0x4CFC 0x4C77 0x4BE8 0x4BA9 0x4B99 0x4CF8 0x4C76 0x4BE3 0x4BA7 0x4B97 0x4CF5 0x4C6E 0x4BDD 0x4BA4 0x4B94 0x4CF3 0x4C65 0x4BD6 0x4BA0 0x4B91 0x4CF1 0x4C5D 0x4BD1 0x4B9B 0x4B8D 0x4CEC 0x4C55 0x4BCE 0x4B99 0x4B8C 0x4CE0 0x4C4F 0x4BCC 0x4B98 0x4B8B 0x4CD1 0x4C49 0x4BC9 0x4B97 0x4B8A 0x4CC1 0x4C45 0x4BC5 0x4B97 0x4B89 0x4CB0 0x4C46 0x4BC3 0x4B97 0x4B88 0x4CA9 0x4C49 0x4BC2 0x4B96 0x4B87 0x4CB0 0x4C49 0x4BC2 0x4B95 0x4B83 0x4CB7 0x4C43 0x4BC2 0x4B94 0x4B81 0x4CB6 0x4C3D 0x4BC2 0x4B93 0x4B7F 0x4CAC 0x4C36 0x4BC2 0x4B91 0x4B7D 0x4CA5 0x4C2E 0x4BBE 0x4B8D 0x4B7B 0x4CA2 0x4C2D 0x4BB9 0x4B87 0x4B78 0x4CA0 0x4C3B 0x4BBD 0x4B89 0x4B7A 0x4CA2 0x4C47 0x4BCA 0x4B9B 0x4B8B 0x4CB0 0x4C40 0x4BD7 0x4BA9 0x4B9A 0x4CBB 0x4C2F 0x4BE4 0x4BB0 0x4B9D 0x4CB6 0x4C2B 0x4BED 0x4BB4 0x4B9F 0x4CAA 0x4C3F 0x4BED 0x4BB4 0x4B9F 0x4CA3 0x4C53 0x4BEA 0x4BAD 0x4B9C 0x4CA2 0x4C53 0x4BE6 0x4BA8 0x4B99 0x4CA2 0x4C4F 0x4BE1 0x4BA6 0x4B96 0x4CA3 0x4C4A 0x4BDA 0x4BA4 0x4B93 0x4CA5 0x4C44 0x4BD5 0x4BA2 0x4B8F 0x4CA6 0x4C3D 0x4BD1 0x4B9E 0x4B8C 0x4CA5 0x4C38 0x4BCD 0x4B9A 0x4B88 0x4CA2 0x4C34 0x4BC9 0x4B95 0x4B83 0x4C9F 0x4C31 0x4BC6 0x4B92 0x4B80 0x4C9B 0x4C2F 0x4BC5 0x4B92 0x4B82 0x4C97 0x4C2C 0x4BC4 0x4B93 0x4B88 0x4C93 0x4C29 0x4BC3 0x4B94 0x4B8B 0x4C8D 0x4C26 0x4BC1 0x4B96 0x4B8B 0x4C89 0x4C22 0x4BBE 0x4B97 0x4B8B 0x4C88 0x4C1F 0x4BBA 0x4B98 0x4B8B 0x4C84 0x4C1B 0x4BB7 0x4B99 0x4B8B 0x4C7B 0x4C19 0x4BB9 0x4B9A 0x4B8D 0x4C57 0x4C0A 0x4BB6 0x4B96 0x4B8D 0x4C49 0x4BFA 0x4BA8 0x4B89 0x4B79 0x4C45 0x4BF8 0x4BA5 0x4B83 0x4B76 0x4C43 0x4BEE 0x4BA3 0x4B7C 0x4B70 0x4C21 0x4BEA 0x4B9F 0x4B78 0x4B70 0x4BC9 0x4BEE 0x4BA3 0x4B8E 0x4B82 0x4C3A 0x4BF2 0x4BB0 0x4B91 0x4B83 0x4C34 0x4BF4 0x4BB2 0x4B91 0x4B84 0x4C32 0x4BF7 0x4BB5 0x4B92 0x4B86 0x4C17 0x4BFB 0x4BB3 0x4B99 0x4B8E 0x4C17 0x4BFB 0x4BB3 0x4B99 0x4B8E 0x4C17 0x4BFB 0x4BB3 0x4B99 0x4B8E>;
                qcom,lut-row-legend = <0x2710 0x2648 0x2580 0x24B8 0x23F0 0x2328 0x2260 0x2198 0x20D0 0x2008 0x1F40 0x1E78 0x1DB0 0x1CE8 0x1C20 0x1B58 0x1A90 0x19C8 0x1900 0x1838 0x1770 0x16A8 0x15E0 0x1518 0x1450 0x1388 0x12C0 0x11F8 0x1130 0x1068 0xFA0 0xED8 0xE10 0xD48 0xC80 0xBB8 0xAF0 0xA28 0x960 0x898 0x7D0 0x708 0x640 0x578 0x4B0 0x3E8 0x384 0x320 0x2BC 0x258 0x1F4 0x190 0x12C 0xC8 0x64 0x0>;
            };
            qcom,pc-temp-z4-lut {
                qcom,lut-col-legend = <0x0 0xA 0x19 0x28 0x32>;
                qcom,lut-data = <0x3DE7 0x3C2E 0x3A96 0x39C0 0x39D8 0x3E4D 0x3BFB 0x3AC4 0x3A1E 0x39E9 0x3DB2 0x3BB0 0x3A6F 0x39F6 0x39CE 0x3CA4 0x3B38 0x3A20 0x39BE 0x3999 0x3BE7 0x3AB0 0x39E5 0x39A3 0x3985 0x3B5F 0x3A54 0x39B8 0x398F 0x397D 0x3AF4 0x3A0E 0x39A8 0x3984 0x3978 0x3A9F 0x39E2 0x39A0 0x397F 0x3974 0x3A5A 0x39CB 0x3999 0x397B 0x3970 0x3A2C 0x39BD 0x3990 0x3976 0x396C 0x3A0D 0x39B6 0x3988 0x3970 0x3968 0x39F7 0x39B3 0x3982 0x396B 0x3963 0x39E7 0x39B0 0x397C 0x3965 0x395F 0x39D9 0x399A 0x397A 0x3960 0x395A 0x39D5 0x397D 0x397A 0x395B 0x3955 0x39F5 0x397D 0x397A 0x3957 0x3950 0x3A1D 0x39AB 0x3979 0x3954 0x394D 0x3A1D 0x39CE 0x3973 0x3950 0x394A 0x39FD 0x39BE 0x396C 0x394D 0x3947 0x39E3 0x399C 0x3963 0x394B 0x3944 0x39D9 0x399C 0x395C 0x3949 0x3941 0x39D2 0x3A01 0x397D 0x3954 0x3946 0x39E1 0x3A5C 0x39DA 0x3990 0x3979 0x3A4E 0x3A5D 0x39FC 0x39B5 0x39A0 0x3AAA 0x3A54 0x39DA 0x39A3 0x3992 0x3AA3 0x3A44 0x39B1 0x3985 0x3977 0x3A83 0x3A16 0x399F 0x3978 0x396B 0x3A65 0x39EA 0x3993 0x3972 0x3965 0x3A4A 0x39DB 0x398D 0x396D 0x3960 0x3A32 0x39D3 0x398A 0x3968 0x395C 0x3A21 0x39D0 0x3988 0x3965 0x3959 0x3A13 0x39D0 0x3988 0x3963 0x3956 0x3A0B 0x39D0 0x3987 0x3961 0x3953 0x3A07 0x39D0 0x3988 0x3961 0x3952 0x3A05 0x39D1 0x398A 0x3961 0x3951 0x3A02 0x39D1 0x398C 0x3962 0x3950 0x39FD 0x39D0 0x398D 0x3966 0x3954 0x39FB 0x39CF 0x398E 0x396D 0x395F 0x39FE 0x39D0 0x398F 0x396F 0x3964 0x3A03 0x39D5 0x3990 0x396D 0x3963 0x3A04 0x39D7 0x3991 0x396B 0x3963 0x39FB 0x39CF 0x398D 0x3968 0x3963 0x39EF 0x39C2 0x3984 0x3964 0x3962 0x39E3 0x39B8 0x397F 0x3962 0x3962 0x39AF 0x3994 0x396F 0x3956 0x3954 0x3994 0x3976 0x3958 0x393D 0x3935 0x398B 0x396F 0x394C 0x3937 0x392D 0x3985 0x3968 0x3940 0x392D 0x3923 0x3995 0x3964 0x393B 0x3928 0x391E 0x39F0 0x396B 0x3946 0x3931 0x3931 0x3993 0x3973 0x3945 0x3935 0x3936 0x399C 0x3971 0x3945 0x3938 0x3938 0x39A0 0x3970 0x3945 0x393A 0x3939 0x39C5 0x396B 0x3949 0x3937 0x3935 0x39C5 0x396B 0x3949 0x3937 0x3935 0x39C5 0x396B 0x3949 0x3937 0x3935>;
                qcom,lut-row-legend = <0x2710 0x2648 0x2580 0x24B8 0x23F0 0x2328 0x2260 0x2198 0x20D0 0x2008 0x1F40 0x1E78 0x1DB0 0x1CE8 0x1C20 0x1B58 0x1A90 0x19C8 0x1900 0x1838 0x1770 0x16A8 0x15E0 0x1518 0x1450 0x1388 0x12C0 0x11F8 0x1130 0x1068 0xFA0 0xED8 0xE10 0xD48 0xC80 0xBB8 0xAF0 0xA28 0x960 0x898 0x7D0 0x708 0x640 0x578 0x4B0 0x3E8 0x384 0x320 0x2BC 0x258 0x1F4 0x190 0x12C 0xC8 0x64 0x0>;
            };
            qcom,pc-temp-z5-lut {
                qcom,lut-col-legend = <0x0 0xA 0x19 0x28 0x32>;
                qcom,lut-data = <0x2E10 0x2FF7 0x34DF 0x3C36 0x377C 0x32C9 0x35F0 0x3B83 0x3FFF 0x4408 0x3611 0x3AFC 0x4048 0x4355 0x4A85 0x38B2 0x3EE8 0x447D 0x478B 0x5025 0x3B09 0x4284 0x4942 0x4B2C 0x52FD 0x3D49 0x4705 0x4CC2 0x4EB2 0x54EF 0x3FF7 0x4C89 0x4CE3 0x4FBC 0x559B 0x43C9 0x5110 0x4C13 0x4E60 0x5428 0x488A 0x5467 0x4BB9 0x4D0E 0x524D 0x4D02 0x5728 0x4D7D 0x4D79 0x527F 0x51BA 0x5860 0x4F90 0x4F03 0x5458 0x5496 0x5879 0x4F8E 0x50E0 0x5677 0x53F6 0x5908 0x4EDE 0x53A1 0x5923 0x5251 0x5F48 0x4E9F 0x5671 0x5BB6 0x5219 0x688C 0x5068 0x58E5 0x5CD7 0x581B 0x693D 0x5266 0x5B5A 0x5CAD 0x5F1D 0x5F87 0x52DE 0x5CF9 0x5C67 0x5E98 0x5814 0x53BF 0x5EF9 0x5D46 0x5974 0x5945 0x5544 0x6017 0x5E93 0x5696 0x5D7A 0x5AD2 0x5F9A 0x5FE9 0x5A1B 0x64D5 0x6003 0x5E41 0x6180 0x6282 0x79A8 0x5E61 0x5B4B 0x6107 0x6C55 0x8A09 0x589A 0x5490 0x5A47 0x7B8C 0x7AF6 0x54D4 0x50C2 0x54C9 0x8529 0x56E2 0x52BE 0x51CD 0x53F5 0x7C79 0x4AAA 0x518F 0x5393 0x53A0 0x67A8 0x5194 0x542D 0x548B 0x5472 0x5DB1 0x5AF0 0x5BCF 0x5573 0x5876 0x5BCF 0x61E7 0x6186 0x56EF 0x5CEA 0x5B44 0x6868 0x6507 0x5C11 0x6059 0x5D42 0x6C77 0x6803 0x62E4 0x63C1 0x62FB 0x6EF4 0x6AE6 0x67B5 0x67C5 0x67D4 0x708C 0x6D93 0x6BFF 0x6C87 0x6AA3 0x7118 0x6FDD 0x6ED1 0x6F16 0x6CD3 0x7155 0x723C 0x70FA 0x6FBD 0x6DDF 0x7134 0x739C 0x7255 0x704D 0x6DD9 0x6FD8 0x72AA 0x7100 0x7150 0x6D83 0x6DA7 0x6FC5 0x6D42 0x72D5 0x6D80 0x6B58 0x6C18 0x6BED 0x748E 0x6D78 0x686B 0x6622 0x6C1D 0x7831 0x6CF1 0x6550 0x6032 0x6C83 0x7B79 0x6B2C 0x6166 0x5B49 0x6F12 0x7C39 0x6931 0x5F44 0x57E3 0x72B8 0x7C8F 0x6735 0x5F82 0x5850 0x7108 0x7CC1 0x6D54 0x643F 0x5944 0x66FD 0x79D1 0x6B26 0x636D 0x55D4 0x5862 0x526B 0x67BA 0x6402 0x5750 0x5848 0x56C3 0x68B6 0x5D6A 0x5F29 0x58F7 0x5F82 0x5BB6 0x5C59 0x60A0 0x5ABB 0x7108 0x4A02 0x5D61 0x56D4 0x712B 0x7414 0x5C09 0x54CB 0x5DB6 0x6B3B 0x66DF 0x4F6D 0x53E2 0x5C31 0x623E 0x602B 0x4A17 0x5204 0x5C36 0x5B47 0x59D5 0x419C 0x5270 0x5495 0x5FAF 0x5CA4 0x419C 0x5270 0x5495 0x5FAF 0x5CA4 0x419C 0x5270 0x5495 0x5FAF 0x5CA4>;
                qcom,lut-row-legend = <0x2710 0x2648 0x2580 0x24B8 0x23F0 0x2328 0x2260 0x2198 0x20D0 0x2008 0x1F40 0x1E78 0x1DB0 0x1CE8 0x1C20 0x1B58 0x1A90 0x19C8 0x1900 0x1838 0x1770 0x16A8 0x15E0 0x1518 0x1450 0x1388 0x12C0 0x11F8 0x1130 0x1068 0xFA0 0xED8 0xE10 0xD48 0xC80 0xBB8 0xAF0 0xA28 0x960 0x898 0x7D0 0x708 0x640 0x578 0x4B0 0x3E8 0x384 0x320 0x2BC 0x258 0x1F4 0x190 0x12C 0xC8 0x64 0x0>;
            };
            qcom,pc-temp-z6-lut {
                qcom,lut-col-legend = <0x0 0xA 0x19 0x28 0x32>;
                qcom,lut-data = <0x3DA0 0x3AE9 0x38EE 0x3843 0x382A 0x3DCE 0x3ADA 0x3913 0x3879 0x384C 0x3D70 0x3AC2 0x38FB 0x386C 0x3844 0x3CC9 0x3A89 0x38E0 0x3859 0x3832 0x3C4A 0x3A35 0x38C3 0x384C 0x3828 0x3BE4 0x39F8 0x38A8 0x3842 0x3823 0x3B92 0x39C6 0x389B 0x383A 0x381F 0x3B50 0x39A3 0x3892 0x3835 0x381A 0x3B1A 0x3990 0x388B 0x3830 0x3817 0x3AF0 0x3983 0x3885 0x382C 0x3814 0x3AD1 0x397B 0x3880 0x3829 0x3811 0x3AB9 0x3976 0x387B 0x3826 0x380E 0x3AA6 0x3970 0x3876 0x3823 0x380C 0x3A95 0x3965 0x3873 0x3820 0x3809 0x3A8F 0x3958 0x3872 0x381E 0x3806 0x3A9A 0x3957 0x3871 0x381B 0x3802 0x3AA9 0x3963 0x3870 0x3819 0x37FF 0x3AA8 0x396D 0x386E 0x3817 0x37FD 0x3A97 0x3965 0x386B 0x3815 0x37FB 0x3A8B 0x3954 0x3866 0x3812 0x37F8 0x3A89 0x3954 0x3861 0x380E 0x37F6 0x3A89 0x3989 0x3873 0x3815 0x37F9 0x3A94 0x39B9 0x38A4 0x383A 0x381A 0x3ACE 0x39B7 0x38B7 0x3851 0x3833 0x3AFD 0x39AF 0x38B0 0x384C 0x382F 0x3AF9 0x39A7 0x38A7 0x3844 0x3826 0x3AE8 0x39A0 0x38A1 0x383E 0x3820 0x3ADB 0x399A 0x389C 0x3839 0x381D 0x3AD1 0x3996 0x3898 0x3835 0x381A 0x3ACA 0x3993 0x3894 0x3832 0x3816 0x3AC7 0x3991 0x3892 0x3830 0x3814 0x3AC5 0x398F 0x3890 0x382E 0x3811 0x3AC5 0x398E 0x388E 0x382B 0x380E 0x3AC6 0x398E 0x388E 0x382A 0x380B 0x3AC7 0x398F 0x388E 0x3828 0x3809 0x3AC9 0x3990 0x388F 0x3827 0x3807 0x3ACA 0x3992 0x3890 0x3829 0x3809 0x3ACC 0x3994 0x3891 0x382D 0x3812 0x3ACF 0x3997 0x3892 0x3830 0x3816 0x3AD5 0x399B 0x3894 0x3830 0x3816 0x3AD9 0x399D 0x3895 0x3831 0x3817 0x3ADA 0x399B 0x3892 0x3831 0x3817 0x3ADB 0x399A 0x388E 0x3831 0x3818 0x3ADB 0x3999 0x388E 0x3831 0x3819 0x3AC7 0x398C 0x3889 0x382A 0x3814 0x3ABB 0x397C 0x3879 0x381A 0x37FD 0x3AB6 0x3978 0x3873 0x3814 0x37F7 0x3AB3 0x3972 0x386D 0x380C 0x37F0 0x3AAC 0x3970 0x386A 0x3808 0x37EE 0x3AAF 0x397A 0x3872 0x3818 0x3800 0x3AC6 0x3984 0x387B 0x381E 0x3805 0x3ACF 0x398A 0x387E 0x3820 0x3808 0x3ADC 0x3993 0x3883 0x3823 0x380B 0x3AF0 0x399F 0x3888 0x3828 0x380F 0x3AF0 0x399F 0x3888 0x3828 0x380F 0x3AF0 0x399F 0x3888 0x3828 0x380F>;
                qcom,lut-row-legend = <0x2710 0x2648 0x2580 0x24B8 0x23F0 0x2328 0x2260 0x2198 0x20D0 0x2008 0x1F40 0x1E78 0x1DB0 0x1CE8 0x1C20 0x1B58 0x1A90 0x19C8 0x1900 0x1838 0x1770 0x16A8 0x15E0 0x1518 0x1450 0x1388 0x12C0 0x11F8 0x1130 0x1068 0xFA0 0xED8 0xE10 0xD48 0xC80 0xBB8 0xAF0 0xA28 0x960 0x898 0x7D0 0x708 0x640 0x578 0x4B0 0x3E8 0x384 0x320 0x2BC 0x258 0x1F4 0x190 0x12C 0xC8 0x64 0x0>;
            };
        };
    };
    vdda_usb_ss_dp_core {
        compatible = "regulator-fixed";
        enable-active-high;
        gpio = <&pm6125_gpios 0x1 0x0>;
        pinctrl-0 = <&usb_eldo9>;
        pinctrl-names = "default";
        regulator-max-microvolt = <0xD6D80>;
        regulator-min-microvolt = <0xD6D80>;
        regulator-name = "vdd_supply";
    };
};

&spmi_bus {
    #address-cells = <0x2>;
    #interrupt-cells = <0x4>;
    #size-cells = <0x0>;
    interrupt-controller;
    qcom,pm7250b@2 {
        #address-cells = <0x1>;
        #size-cells = <0x0>;
        compatible = "qcom,spmi-pmic";
        reg = <0x2 0x0>;
        pm7250b_adc_tm: adc_tm@3500 {
            #address-cells = <0x1>;
            #size-cells = <0x0>;
            #thermal-sensor-cells = <0x1>;
            compatible = "qcom,spmi-adc-tm5";
            interrupt-names = "pm-adc-tm5";
            interrupts = <0x2 0x35 0x0 0x1>;
            reg = <0x3500>;
            status = "ok";
            charger_skin_therm@4d {
                io-channels = <&pm7250b_vadc 0x4D>;
                qcom,hw-settle-time-us = <0xC8>;
                qcom,ratiometric;
                reg = <0x0>;
            };
            conn_therm@4f {
                io-channels = <&pm7250b_vadc 0x4F>;
                qcom,hw-settle-time-us = <0xC8>;
                qcom,ratiometric;
                reg = <0x1>;
            };
        };
        bcl_soc: bcl-soc {
            #thermal-sensor-cells = <0x0>;
            compatible = "qcom,msm-bcl-soc";
        };
        pm7250b_bcl: bcl@1d00 {
            #thermal-sensor-cells = <0x1>;
            compatible = "qcom,bcl-v5";
            interrupt-names = "bcl-lvl0", "bcl-lvl1", "bcl-lvl2";
            interrupts = <0x2 0x1D 0x0 0x0 0x2 0x1D 0x1 0x0 0x2 0x1D 0x2 0x0>;
            reg = <0x1D00>;
        };
        pm7250b_clkdiv: clock-controller@5b00 {
            #clock-cells = <0x1>;
            assigned-clock-rates = <0x124F800>;
            assigned-clocks = <&pm7250b_clkdiv 0x1>;
            clock-names = "xo";
            clock-output-names = "pm7250b_div_clk1";
            clocks = <&rpmcc 0x0>;
            compatible = "qcom,spmi-clkdiv";
            qcom,num-clkdivs = <0x1>;
            reg = <0x5B00>;
        };
        pm7250b_gpios: pinctrl@c000 {
            #gpio-cells = <0x2>;
            #interrupt-cells = <0x2>;
            compatible = "qcom,pm7250b-gpio";
            gpio-controller;
            interrupt-controller;
            reg = <0xC000>;
            disp_lcd_bias_en {
                disp_lcd_bias_en_default: disp_lcd_bias_en_default {
                    bias-disable;
                    function = "func1";
                    input-disable;
                    output-enable;
                    pins = "gpio5";
                    power-source = <0x0>;
                    qcom,drive-strength = <0x2>;
                };
            };
            pm7250b_smb_int_default: pm7250b_smb_int_default {
                bias-pull-up;
                function = "gpio";
                input-enable;
                pins = "gpio6";
                power-source = <0x0>;
                qcom,pull-up-strength = <0x0>;
            };
        };
        pm7250b_charger: qcom,qpnp-smb5 {
            #address-cells = <0x1>;
            #cooling-cells = <0x2>;
            #io-channel-cells = <0x1>;
            #size-cells = <0x1>;
            compatible = "qcom,pm7250b-smb5";
            depends-on-supply = <&pm7250b_vadc>;
            dpdm-supply = <&usb2_phy0>;
            io-channel-names = "usb_in_voltage", "usb_in_current", "chg_temp", "die_temp", "conn_temp", "sbux_res", "vph_voltage", "skin_temp", "resistance_id", "voltage_now", "temp", "capacity", "voltage_ocv", "voltage_avg", "debug_battery", "real_capacity", "cc_soc", "current_now", "voltage_max", "charge_full", "charge_counter", "cycle_count", "charge_full_design", "time_to_full_now";
            io-channels = <&pm7250b_vadc 0x8 &pm7250b_vadc 0x7 &pm7250b_vadc 0x9 &pm7250b_vadc 0x6 &pm7250b_vadc 0x4F &pm7250b_vadc 0x99 &pm7250b_vadc 0x83 &pm7250b_vadc 0x4D &pm7250b_qg 0x4B &pm7250b_qg 0x46 &pm7250b_qg 0x45 &pm7250b_qg 0x42 &pm7250b_qg 0x47 &pm7250b_qg 0x5D &pm7250b_qg 0x4E &pm7250b_qg 0x44 &pm7250b_qg 0x5B &pm7250b_qg 0x48 &pm7250b_qg 0x2D &pm7250b_qg 0x53 &pm7250b_qg 0x49 &pm7250b_qg 0x52 &pm7250b_qg 0x54 &pm7250b_qg 0x56>;
            qcom,auto-recharge-soc = <0x62>;
            qcom,battery-data = <&qrd_batterydata>;
            qcom,charger-temp-max = <0x320>;
            qcom,fcc-step-delay-ms = <0x64>;
            qcom,fcc-step-size-ua = <0x186A0>;
            qcom,fcc-stepping-enable;
            qcom,hvdcp2-12v-max-icl-ua = <0x16E360>;
            qcom,hvdcp2-max-icl-ua = <0x1E8480>;
            qcom,sec-charger-config = <0x1>;
            qcom,smb-internal-pull-kohm = <0x0>;
            qcom,smb-temp-max = <0x320>;
            qcom,step-charging-enable;
            qcom,suspend-input-on-debug-batt;
            qcom,sw-jeita-enable;
            qcom,thermal-mitigation = <0x7A1200 0x7270E0 0x6ACFC0 0x632EA0 0x5B8D80 0x53EC60 0x4C4B40 0x44AA20 0x3D0900 0x3567E0 0x2DC6C0 0x2625A0 0x1E8480 0x16E360 0xF4240 0x7A120>;
            status = "ok";
            qcom,batif@1200 {
                interrupt-names = "bat-temp", "bat-ov", "bat-low", "bat-therm-or-id-missing", "bat-terminal-missing", "buck-oc", "vph-ov";
                interrupts = <0x2 0x12 0x0 0x1 0x2 0x12 0x2 0x3 0x2 0x12 0x3 0x3 0x2 0x12 0x4 0x3 0x2 0x12 0x5 0x3 0x2 0x12 0x6 0x3 0x2 0x12 0x7 0x3>;
                reg = <0x1200>;
            };
            qcom,chg-sdam@b000 {
                reg = <0xB000>;
            };
            qcom,chgr@1000 {
                interrupt-names = "chgr-error", "chg-state-change", "step-chg-state-change", "step-chg-soc-update-fail", "step-chg-soc-update-req", "fg-fvcal-qualified", "vph-alarm", "vph-drop-prechg";
                interrupts = <0x2 0x10 0x0 0x1 0x2 0x10 0x1 0x1 0x2 0x10 0x2 0x1 0x2 0x10 0x3 0x1 0x2 0x10 0x4 0x1 0x2 0x10 0x5 0x1 0x2 0x10 0x6 0x1 0x2 0x10 0x7 0x1>;
                reg = <0x1000>;
            };
            qcom,dc@1400 {
                interrupt-names = "dcin-vashdn", "dcin-uv", "dcin-ov", "dcin-plugin", "dcin-revi", "dcin-pon", "dcin-en";
                interrupts = <0x2 0x14 0x1 0x3 0x2 0x14 0x2 0x3 0x2 0x14 0x3 0x3 0x2 0x14 0x4 0x3 0x2 0x14 0x5 0x3 0x2 0x14 0x6 0x1 0x2 0x14 0x7 0x1>;
                reg = <0x1400>;
            };
            qcom,dcdc@1100 {
                interrupt-names = "otg-fail", "otg-oc-disable-sw", "otg-oc-hiccup", "bsm-active", "high-duty-cycle", "input-current-limiting", "concurrent-mode-disable", "switcher-power-ok";
                interrupts = <0x2 0x11 0x0 0x1 0x2 0x11 0x1 0x1 0x2 0x11 0x2 0x1 0x2 0x11 0x3 0x3 0x2 0x11 0x4 0x3 0x2 0x11 0x5 0x3 0x2 0x11 0x6 0x1 0x2 0x11 0x7 0x3>;
                reg = <0x1100>;
            };
            qcom,misc@1600 {
                interrupt-names = "wdog-snarl", "wdog-bark", "aicl-fail", "aicl-done", "smb-en", "imp-trigger", "temp-change", "temp-change-smb";
                interrupts = <0x2 0x16 0x0 0x1 0x2 0x16 0x1 0x1 0x2 0x16 0x2 0x1 0x2 0x16 0x3 0x1 0x2 0x16 0x4 0x3 0x2 0x16 0x5 0x1 0x2 0x16 0x6 0x1 0x2 0x16 0x7 0x1>;
                reg = <0x1600>;
            };
            smb5_vbus: qcom,smb5-vbus {
                regulator-name = "smb5-vbus";
            };
            smb5_vconn: qcom,smb5-vconn {
                regulator-name = "smb5-vconn";
            };
            qcom,typec@1500 {
                interrupt-names = "typec-or-rid-detect-change", "typec-vpd-detect", "typec-cc-state-change", "typec-vconn-oc", "typec-vbus-change", "typec-attach-detach", "typec-legacy-cable-detect", "typec-try-snk-src-detect";
                interrupts = <0x2 0x15 0x0 0x1 0x2 0x15 0x1 0x1 0x2 0x15 0x2 0x1 0x2 0x15 0x3 0x1 0x2 0x15 0x4 0x1 0x2 0x15 0x5 0x1 0x2 0x15 0x6 0x1 0x2 0x15 0x7 0x1>;
                reg = <0x1500>;
            };
            qcom,usb@1300 {
                interrupt-names = "usbin-collapse", "usbin-vashdn", "usbin-uv", "usbin-ov", "usbin-plugin", "usbin-revi-change", "usbin-src-change", "usbin-icl-change";
                interrupts = <0x2 0x13 0x0 0x3 0x2 0x13 0x1 0x3 0x2 0x13 0x2 0x3 0x2 0x13 0x3 0x3 0x2 0x13 0x4 0x3 0x2 0x13 0x5 0x3 0x2 0x13 0x6 0x1 0x2 0x13 0x7 0x1>;
                reg = <0x1300>;
            };
        };
        pm7250b_tz: qcom,temp-alarm@2400 {
            #thermal-sensor-cells = <0x0>;
            compatible = "qcom,spmi-temp-alarm";
            interrupts = <0x2 0x24 0x0 0x3>;
            io-channel-names = "thermal";
            io-channels = <&pm7250b_vadc 0x6>;
            qcom,temperature-threshold-set = <0x1>;
            reg = <0x2400>;
        };
        pm7250b_pdphy: qcom,usb-pdphy@1700 {
            #io-channel-cells = <0x1>;
            compatible = "qcom,qpnp-pdphy";
            interrupt-names = "sig-tx", "sig-rx", "msg-tx", "msg-rx", "msg-tx-failed", "msg-tx-discarded", "msg-rx-discarded", "fr-swap";
            interrupts = <0x2 0x17 0x0 0x1 0x2 0x17 0x1 0x1 0x2 0x17 0x2 0x1 0x2 0x17 0x3 0x1 0x2 0x17 0x4 0x1 0x2 0x17 0x5 0x1 0x2 0x17 0x6 0x1 0x2 0x17 0x7 0x1>;
            io-channel-names = "pd_active", "typec_cc_orientation", "connector_type", "typec_power_role", "pd_usb_suspend_supported", "typec_src_rp", "pd_in_hard_reset", "pr_current_max", "pr_swap", "pd_voltage_min", "pd_voltage_max", "real_type", "typec_mode", "pe_start";
            io-channels = <&pm7250b_charger 0x4 &pm7250b_charger 0x3 &pm7250b_charger 0xD &pm7250b_charger 0x2 &pm7250b_charger 0x1F &pm7250b_charger 0x1D &pm7250b_charger 0x1E &pm7250b_charger 0x0 &pm7250b_charger 0x20 &pm7250b_charger 0xC &pm7250b_charger 0xB &pm7250b_charger 0xA &pm7250b_charger 0x1 &pm7250b_charger 0x7>;
            qcom,default-sink-caps = <0x1388 0xBB8 0x2328 0xBB8 0x2EE0 0x8CA>;
            reg = <0x1700>;
            vbus-supply = <&smb5_vbus>;
            vconn-supply = <&smb5_vconn>;
            vdd-pdphy-supply = <&L15A>;
        };
        pm7250b_qg: qpnp,qg {
            #address-cells = <0x1>;
            #io-channel-cells = <0x1>;
            #size-cells = <0x1>;
            compatible = "qcom,pm7250b-qg";
            depends-on-supply = <&pm6125_rtc>;
            io-channel-names = "batt-therm", "batt-id", "input_current_limited", "recharge_soc", "force_recharge", "charge_done";
            io-channels = <&pm7250b_vadc 0x2A &pm7250b_vadc 0x4B &pm7250b_charger 0x37 &pm7250b_charger 0x3F &pm7250b_charger 0x40 &pm7250b_charger 0x39>;
            qcom,bass-enable;
            qcom,cl-feedback-on;
            qcom,fvss-enable;
            qcom,fvss-vbatt-mv = <0xDAC>;
            qcom,hold-soc-while-full;
            qcom,linearize-soc;
            qcom,qg-iterm-ma = <0x96>;
            qcom,s3-entry-fifo-length = <0x2>;
            qcom,soc_decimal_rate = <0x0 0x20 0xA 0x1E 0x14 0x1C 0x1E 0x1C 0x28 0x1C 0x32 0x1C 0x3C 0x1C 0x46 0x1C 0x50 0x1C 0x5A 0x1A 0x5F 0xA 0x63 0x5>;
            qcom,tcss-enable;
            qcom,use-cp-iin-sns;
            qcom,vbatt-cutoff-mv = <0xD48>;
            qcom,vbatt-empty-cold-mv = <0xC1C>;
            qcom,vbatt-empty-mv = <0xC80>;
            qcom,vbatt-low-cold-mv = <0xED8>;
            qcom,vbatt-low-mv = <0xDAC>;
            status = "ok";
            qcom,qg-sdam@b100 {
                reg = <0xB100>;
                status = "okay";
            };
            qcom,qgauge@4800 {
                interrupt-names = "qg-batt-missing", "qg-vbat-low", "qg-vbat-empty", "qg-fifo-done", "qg-good-ocv";
                interrupts = <0x2 0x48 0x0 0x3 0x2 0x48 0x1 0x3 0x2 0x48 0x2 0x1 0x2 0x48 0x3 0x1 0x2 0x48 0x4 0x1>;
                reg = <0x4800>;
                status = "okay";
            };
        };
        pm7250b_vadc: vadc@3100 {
            #address-cells = <0x1>;
            #io-channel-cells = <0x1>;
            #size-cells = <0x0>;
            compatible = "qcom,spmi-adc5";
            interrupt-names = "eoc-int-en-set";
            interrupts = <0x2 0x31 0x0 0x1>;
            io-channel-ranges;
            qcom,adc-vdd-reference = <0x753>;
            reg = <0x3100>;
            reg-names = "adc5-usr-base";
            bat_id@4b {
                label = "bat_id";
                qcom,hw-settle-time = <0xC8>;
                qcom,pre-scaling = <0x1 0x1>;
                qcom,ratiometric;
                reg = <0x4B>;
            };
            bat_therm@4a {
                label = "bat_therm";
                qcom,hw-settle-time = <0xC8>;
                qcom,pre-scaling = <0x1 0x1>;
                qcom,ratiometric;
                reg = <0x4A>;
            };
            bat_therm_30k@2a {
                label = "bat_therm_30k";
                qcom,hw-settle-time = <0xC8>;
                qcom,pre-scaling = <0x1 0x1>;
                qcom,ratiometric;
                reg = <0x2A>;
            };
            bat_therm_400k@6a {
                label = "bat_therm_400k";
                qcom,hw-settle-time = <0xC8>;
                qcom,pre-scaling = <0x1 0x1>;
                qcom,ratiometric;
                reg = <0x6A>;
            };
            charger_skin_therm@4d {
                label = "charger_skin_therm";
                qcom,hw-settle-time = <0xC8>;
                qcom,pre-scaling = <0x1 0x1>;
                qcom,ratiometric;
                reg = <0x4D>;
            };
            chg_sbux@99 {
                label = "chg_sbux";
                qcom,pre-scaling = <0x1 0x3>;
                reg = <0x99>;
            };
            chg_temp@9 {
                label = "chg_temp";
                qcom,pre-scaling = <0x1 0x1>;
                reg = <0x9>;
            };
            conn_therm@4f {
                label = "conn_therm";
                qcom,hw-settle-time = <0xC8>;
                qcom,pre-scaling = <0x1 0x1>;
                qcom,ratiometric;
                reg = <0x4F>;
            };
            die_temp@2 {
                label = "die_temp";
                qcom,pre-scaling = <0x1 0x1>;
                reg = <0x6>;
            };
            mid_chg_div6@1e {
                label = "chg_mid";
                qcom,pre-scaling = <0x1 0x6>;
                reg = <0x1E>;
            };
            ref_gnd@0 {
                label = "ref_gnd";
                qcom,pre-scaling = <0x1 0x1>;
                reg = <0x0>;
            };
            smb1390_therm@e {
                label = "smb1390_therm";
                qcom,hw-settle-time = <0xC8>;
                qcom,pre-scaling = <0x1 0x1>;
                qcom,scale-fn-type = <0x10>;
                reg = <0xE>;
            };
            usb_in_i_uv@7 {
                label = "usb_in_i_uv";
                qcom,pre-scaling = <0x1 0x1>;
                reg = <0x7>;
            };
            usb_in_v_div_16@8 {
                label = "usb_in_v_div_16";
                qcom,pre-scaling = <0x1 0x10>;
                reg = <0x8>;
            };
            vbat_sns@84 {
                label = "vbat_sns";
                qcom,pre-scaling = <0x1 0x3>;
                reg = <0x84>;
            };
            vph_pwr@83 {
                label = "vph_pwr";
                qcom,pre-scaling = <0x1 0x3>;
                reg = <0x83>;
            };
            vref_1p25@1 {
                label = "vref_1p25";
                qcom,pre-scaling = <0x1 0x1>;
                reg = <0x1>;
            };
        };
    };
    qcom,pm7250b@3 {
        #address-cells = <0x1>;
        #size-cells = <0x0>;
        compatible = "qcom,spmi-pmic";
        reg = <0x3 0x0>;
        pm7250b_vib: qcom,vibrator@5300 {
            compatible = "qcom,qpnp-vibrator-ldo";
            qcom,disable-overdrive;
            qcom,vib-ldo-volt-uv = <0x2DC6C0>;
            reg = <0x5300>;
        };
    };
};

&thermal_zones {
    charger-therm-usr {
        polling-delay = <0x0>;
        polling-delay-passive = <0x0>;
        thermal-governor = "user_space";
        thermal-sensors = <&pm7250b_adc_tm 0x0>;
        wake-capable-sensor;
        trips {
            active-config0 {
                hysteresis = <0x3E8>;
                temperature = <0x1E848>;
                type = "passive";
            };
        };
    };
    conn-therm-usr {
        polling-delay = <0x0>;
        polling-delay-passive = <0x0>;
        thermal-governor = "user_space";
        thermal-sensors = <&pm7250b_adc_tm 0x1>;
        wake-capable-sensor;
        trips {
            active-config0 {
                hysteresis = <0x3E8>;
                temperature = <0x1E848>;
                type = "passive";
            };
        };
    };
    pa-therm0 {
        cooling-maps {
            modem_cdev0 {
                cooling-device = <&modem_pa 0x1 0x1>;
                trip = <&pa_therm0_trip0>;
            };
            modem_cdev1 {
                cooling-device = <&modem_pa 0x2 0x2>;
                trip = <&pa_therm0_trip1>;
            };
            modem_cdev2 {
                cooling-device = <&modem_pa 0x3 0x3>;
                trip = <&pa_therm0_trip2>;
            };
        };
        trips {
            pa-therm0-trip0 {
                hysteresis = <0x7D0>;
                temperature = <0xCB20>;
                type = "passive";
            };
            pa-therm0-trip1 {
                hysteresis = <0x7D0>;
                temperature = <0xD2F0>;
                type = "passive";
            };
            pa-therm0-trip2 {
                hysteresis = <0xFA0>;
                temperature = <0xEA60>;
                type = "passive";
            };
        };
    };
    pm6125-tz {
        cooling-maps {
            trip0_cpu0 {
                cooling-device = <&CPU0 0x7 0x7>;
                trip = <&pm6125_trip0>;
            };
            trip0_cpu4 {
                cooling-device = <&CPU4 0x6 0xFFFFFFFF>;
                trip = <&pm6125_trip0>;
            };
            trip1_cpu1 {
                cooling-device = <&cpu1_pause 0x1 0x1>;
                trip = <&pm6125_trip1>;
            };
            trip1_cpu2 {
                cooling-device = <&cpu2_pause 0x1 0x1>;
                trip = <&pm6125_trip1>;
            };
            trip1_cpu3 {
                cooling-device = <&cpu3_pause 0x1 0x1>;
                trip = <&pm6125_trip1>;
            };
            trip1_cpu4 {
                cooling-device = <&cpu4_pause 0x1 0x1>;
                trip = <&pm6125_trip1>;
            };
            trip1_cpu5 {
                cooling-device = <&cpu5_pause 0x1 0x1>;
                trip = <&pm6125_trip1>;
            };
            trip1_cpu6 {
                cooling-device = <&cpu6_pause 0x1 0x1>;
                trip = <&pm6125_trip1>;
            };
            trip1_cpu7 {
                cooling-device = <&cpu7_pause 0x1 0x1>;
                trip = <&pm6125_trip1>;
            };
        };
    };
    pm7250b-bcl-lvl0 {
        polling-delay = <0x0>;
        polling-delay-passive = <0x64>;
        thermal-sensors = <&pm7250b_bcl 0x5>;
        trips {
            b-bcl-lvl0 {
                hysteresis = <0x1>;
                temperature = <0x1>;
                type = "passive";
            };
        };
        cooling-maps {
            lbat0_cdsp {
                cooling-device = <&cdsp_sw 0x2 0x2>;
                trip = <&b_bcl_lvl0>;
            };
            lbat0_cpu6 {
                cooling-device = <&cpu6_pause 0x1 0x1>;
                trip = <&b_bcl_lvl0>;
            };
            lbat0_cpu7 {
                cooling-device = <&cpu7_pause 0x1 0x1>;
                trip = <&b_bcl_lvl0>;
            };
            lbat0_cpufreq4 {
                cooling-device = <&CPU4 0x2 0x2>;
                trip = <&b_bcl_lvl0>;
            };
            lbat0_gpu {
                cooling-device = <&msm_gpu 0x2 0x2>;
                trip = <&b_bcl_lvl0>;
            };
        };
    };
    pm7250b-bcl-lvl1 {
        polling-delay = <0x0>;
        polling-delay-passive = <0x64>;
        thermal-sensors = <&pm7250b_bcl 0x6>;
        trips {
            b-bcl-lvl1 {
                hysteresis = <0x1>;
                temperature = <0x1>;
                type = "passive";
            };
        };
        cooling-maps {
            lbat1_cdsp {
                cooling-device = <&cdsp_sw 0x4 0x4>;
                trip = <&b_bcl_lvl1>;
            };
            lbat1_cpu4 {
                cooling-device = <&cpu4_pause 0x1 0x1>;
                trip = <&b_bcl_lvl1>;
            };
            lbat1_cpu5 {
                cooling-device = <&cpu5_pause 0x1 0x1>;
                trip = <&b_bcl_lvl1>;
            };
            lbat1_gpu {
                cooling-device = <&msm_gpu 0x4 0x4>;
                trip = <&b_bcl_lvl1>;
            };
        };
    };
    pm7250b-bcl-lvl2 {
        polling-delay = <0x0>;
        polling-delay-passive = <0x64>;
        thermal-sensors = <&pm7250b_bcl 0x7>;
        trips {
            b-bcl-lvl2 {
                hysteresis = <0x1>;
                temperature = <0x1>;
                type = "passive";
            };
        };
        cooling-maps {
            lbat2_cdsp {
                cooling-device = <&cdsp_sw 0x4 0x4>;
                trip = <&b_bcl_lvl2>;
            };
            lbat2_gpu {
                cooling-device = <&msm_gpu 0x4 0xFFFFFFFF>;
                trip = <&b_bcl_lvl2>;
            };
        };
    };
    pm7250b-ibat-lvl0 {
        polling-delay = <0x0>;
        polling-delay-passive = <0x0>;
        thermal-sensors = <&pm7250b_bcl 0x0>;
        trips {
            ibat-lvl0 {
                hysteresis = <0xC8>;
                temperature = <0x157C>;
                type = "passive";
            };
        };
    };
    pm7250b-ibat-lvl1 {
        polling-delay = <0x0>;
        polling-delay-passive = <0x0>;
        thermal-sensors = <&pm7250b_bcl 0x1>;
        trips {
            ibat-lvl1 {
                hysteresis = <0xC8>;
                temperature = <0x1770>;
                type = "passive";
            };
        };
    };
    pm7250b-tz {
        polling-delay = <0x0>;
        polling-delay-passive = <0x64>;
        thermal-sensors = <&pm7250b_tz>;
        trips {
            trip0 {
                hysteresis = <0x0>;
                temperature = <0x17318>;
                type = "passive";
            };
            trip1 {
                hysteresis = <0x0>;
                temperature = <0x1C138>;
                type = "passive";
            };
            trip2 {
                hysteresis = <0x0>;
                temperature = <0x23668>;
                type = "passive";
            };
        };
        cooling-maps {
            trip0_bat {
                cooling-device = <&pm7250b_charger 0xF 0xF>;
                trip = <&pm7250b_trip0>;
            };
            trip1_bat {
                cooling-device = <&pm7250b_charger 0x10 0x10>;
                trip = <&pm7250b_trip1>;
            };
        };
    };
    quiet-therm {
        polling-delay-passive = <0x7D0>;
        cooling-maps {
            gold_cdev {
                cooling-device = <&CPU4 0x0 0x4>;
                trip = <&quiet_gold_trip>;
            };
            gpu_cdev {
                cooling-device = <&msm_gpu 0x0 0x3>;
                trip = <&quiet_gpu_trip>;
            };
            hvx_cdev {
                cooling-device = <&cdsp_sw 0x4 0x4>;
                trip = <&quiet_hvx_trip>;
            };
            mdm_cdev0 {
                cooling-device = <&modem_proc 0x1 0x1>;
                trip = <&quiet_modem_trip0>;
            };
            mdm_cdev1 {
                cooling-device = <&modem_proc 0x3 0x3>;
                trip = <&quiet_modem_trip1>;
            };
            silver_cdev {
                cooling-device = <&CPU0 0x0 0x2>;
                trip = <&quiet_silver_trip>;
            };
            quiet_batt_cdev1 {
                cooling-device = <&pm7250b_charger 0x8 0x8>;
                trip = <&quiet_batt_trip0>;
            };
            quiet_batt_cdev2 {
                cooling-device = <&pm7250b_charger 0xC 0xC>;
                trip = <&quiet_batt_trip1>;
            };
            quiet_batt_cdev3 {
                cooling-device = <&pm7250b_charger 0xE 0xE>;
                trip = <&quiet_batt_trip2>;
            };
            quiet_batt_cdev4 {
                cooling-device = <&pm7250b_charger 0x10 0x10>;
                trip = <&quiet_batt_trip3>;
            };
        };
        trips {
            batt-trip0 {
                hysteresis = <0x7D0>;
                temperature = <0xA028>;
                type = "passive";
            };
            batt-trip1 {
                hysteresis = <0x7D0>;
                temperature = <0xA7F8>;
                type = "passive";
            };
            batt-trip2 {
                hysteresis = <0x7D0>;
                temperature = <0xAFC8>;
                type = "passive";
            };
            batt-trip3 {
                hysteresis = <0x7D0>;
                temperature = <0xB798>;
                type = "passive";
            };
            batt-trip4 {
                hysteresis = <0x3E8>;
                temperature = <0xBB80>;
                type = "passive";
            };
            gold-trip {
                hysteresis = <0x0>;
                temperature = <0xB798>;
                type = "passive";
            };
            gpu-trip {
                hysteresis = <0xFA0>;
                temperature = <0xBB80>;
                type = "passive";
            };
            hvx-trip {
                hysteresis = <0xFA0>;
                temperature = <0xCB20>;
                type = "passive";
            };
            modem-trip0 {
                hysteresis = <0x7D0>;
                temperature = <0xA410>;
                type = "passive";
            };
            modem-trip1 {
                hysteresis = <0xFA0>;
                temperature = <0xEA60>;
                type = "passive";
            };
            silver-trip {
                hysteresis = <0x0>;
                temperature = <0xC350>;
                type = "passive";
            };
        };
    };
    socd {
        polling-delay = <0x0>;
        polling-delay-passive = <0x64>;
        trips {
            soc-trip {
                hysteresis = <0x0>;
                temperature = <0x5A>;
                type = "passive";
            };
            thermal-engine-trip {
                hysteresis = <0x0>;
                temperature = <0x64>;
                type = "passive";
            };
            thermal-hal-trip {
                hysteresis = <0x0>;
                temperature = <0x64>;
                type = "passive";
            };
        };
        cooling-maps {
            soc_cpu4 {
                cooling-device = <&cpu4_pause 0x1 0x1>;
                trip = <&soc_trip>;
            };
            soc_cpu5 {
                cooling-device = <&cpu5_pause 0x1 0x1>;
                trip = <&soc_trip>;
            };
            soc_cpu6 {
                cooling-device = <&cpu6_pause 0x1 0x1>;
                trip = <&soc_trip>;
            };
            soc_cpu7 {
                cooling-device = <&cpu7_pause 0x1 0x1>;
                trip = <&soc_trip>;
            };
        };
    };
};

&tlmm {
    fpc_reset_int: fpc_reset_int {
        fpc_int_low: int_low {
            config {
                bias-pull-down;
                drive-strength = <0x2>;
                input-enable;
                pins = "gpio97";
            };
            mux {
                function = "gpio";
                pins = "gpio97";
            };
        };
        fpc_reset_high: reset_high {
            config {
                bias-disable;
                drive-strength = <0x2>;
                output-high;
                pins = "gpio104";
            };
            mux {
                function = "gpio";
                pins = "gpio104";
            };
        };
        fpc_reset_low: reset_low {
            config {
                bias-disable;
                drive-strength = <0x2>;
                output-low;
                pins = "gpio104";
            };
            mux {
                function = "gpio";
                pins = "gpio104";
            };
        };
    };
    smb_int_default {
        config {
            bias-pull-up;
            input-enable;
            pins = "gpio105";
        };
        mux {
            function = "gpio";
            pins = "gpio105";
        };
    };
};

&ufshc_mem {
    qcom,vddp-ref-clk-max-microamp = <0x64>;
    qcom,vddp-ref-clk-supply = <&L18A>;
    reset-gpios = <&tlmm 0x71 0x1>;
    reset-names = "rst";
    resets = <&gcc 0x4>;
    status = "ok";
    vcc-max-microamp = "\f5";
    vcc-supply = <&L24A>;
    vccq2-max-microamp = "\f5";
    vccq2-supply = <&L11A>;
    vdd-hba-fixed-regulator;
    vdd-hba-supply = <&gcc_ufs_phy_gdsc>;
};

&ufsphy_mem {
    compatible = "qcom,ufs-phy-qmp-v4-khaje";
    status = "ok";
    vdda-phy-max-microamp = <0x14EC4>;
    vdda-phy-supply = <&L4A>;
    vdda-pll-max-microamp = <0x477C>;
    vdda-pll-supply = <&L18A>;
};

&usb0 {
    extcon = <&pm7250b_pdphy &pm7250b_charger &eud>;
};

&usb_qmp_dp_phy {
    vdd-supply = <&vdda_usb_ss_dp_core>;
};

